[part 2 of 2: package /MICROSAR/Dcm_swc/ComponentTypes]
AUTOSAR XML (schema 00048)
package /MICROSAR/Dcm_swc/ComponentTypes
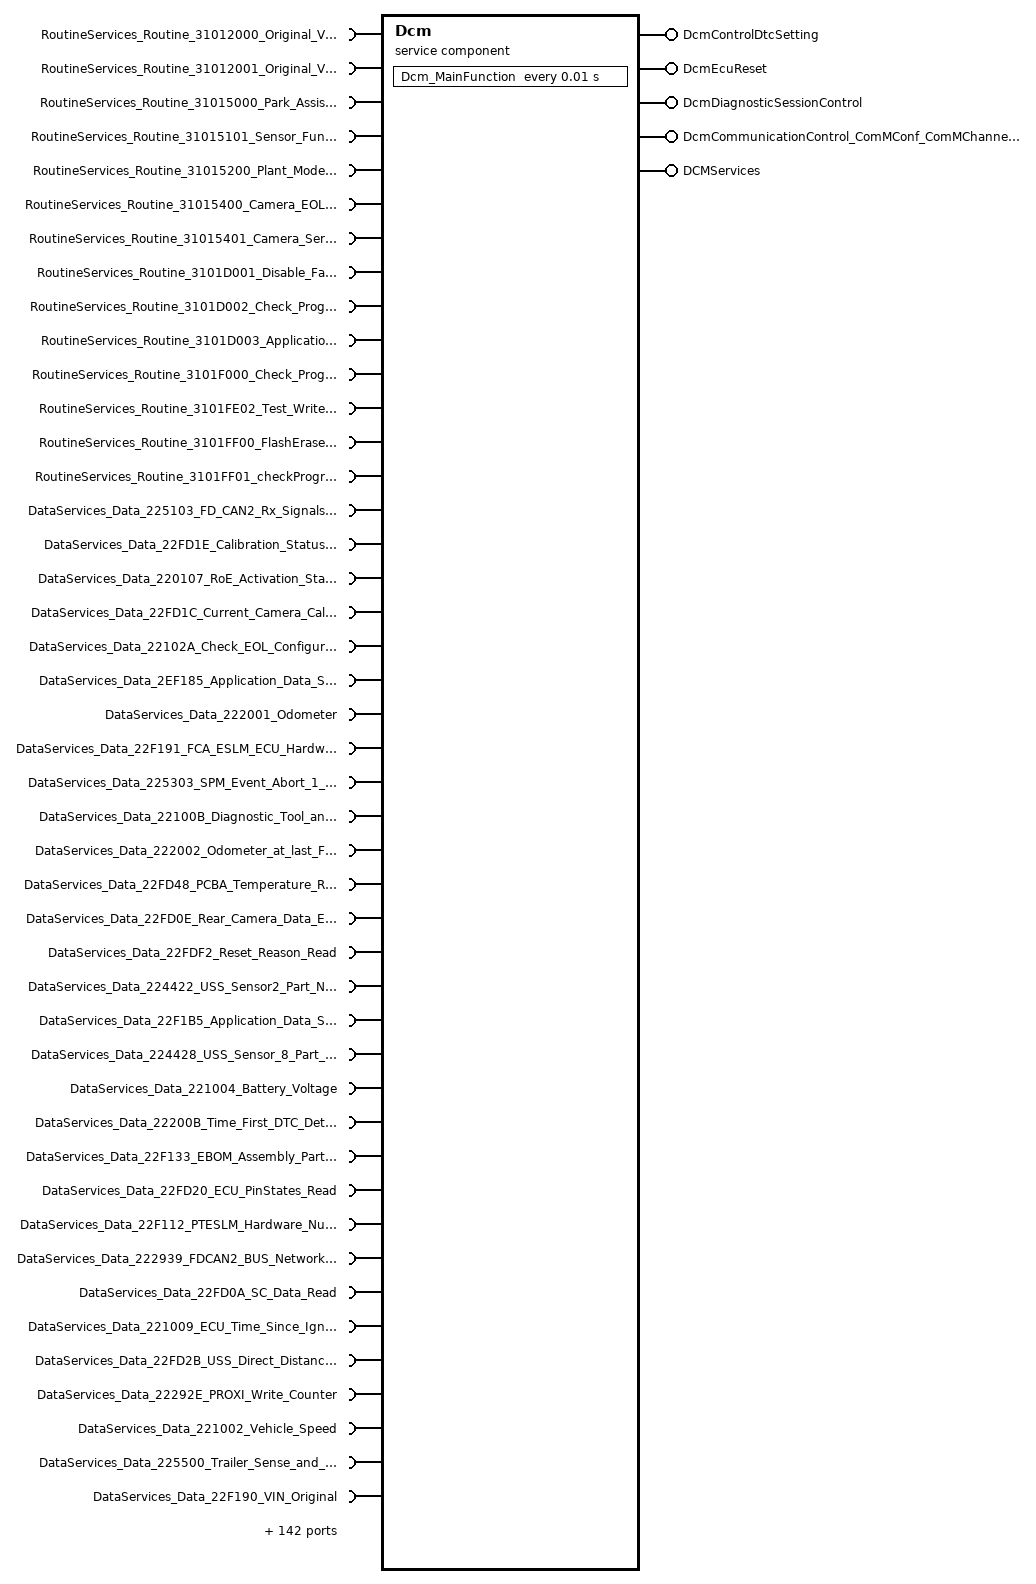
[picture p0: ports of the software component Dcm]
  service sw component type Dcm: category=SERVICE_COMPONENT
    5 x provide port:
      DcmControlDtcSetting: provided-interface=DcmControlDtcSetting
      DcmEcuReset: mode-switch-sender-com-spec{mode-group=DcmEcuReset, mode-switched-ack=timeout=0}, provided-interface=DcmEcuReset
      DcmDiagnosticSessionControl: provided-interface=DcmDiagnosticSessionControl
      DcmCommunicationControl_ComMConf_ComMChannel_CN_FDCAN2_28a8fc44: provided-interface=DcmCommunicationControl_ComMConf_ComMChannel_CN_FDCAN2_28a8fc44
      DCMServices: provided-interface=DCMServices
    186 x require port:
      RoutineServices_Routine_31012000_Original_VIN_Lock: required-interface=RoutineServices_Routine_31012000_Original_VIN_Lock
      RoutineServices_Routine_31012001_Original_VIN_Unlock: required-interface=RoutineServices_Routine_31012001_Original_VIN_Unlock
      RoutineServices_Routine_31015000_Park_Assist_ON_OFF_State_Start: required-interface=RoutineServices_Routine_31015000_Park_Assist_ON_OFF_State_Start
      RoutineServices_Routine_31015101_Sensor_Functional_Test_Start: required-interface=RoutineServices_Routine_31015101_Sensor_Functional_Test_Start
      RoutineServices_Routine_31015200_Plant_Mode_Routine_Start: required-interface=RoutineServices_Routine_31015200_Plant_Mode_Routine_Start
      RoutineServices_Routine_31015400_Camera_EOL_Calibration_Start: required-interface=RoutineServices_Routine_31015400_Camera_EOL_Calibration_Start
      RoutineServices_Routine_31015401_Camera_Service_Calibration_Start: required-interface=RoutineServices_Routine_31015401_Camera_Service_Calibration_Start
      RoutineServices_Routine_3101D001_Disable_Fail_safe_reaction_Start: required-interface=RoutineServices_Routine_3101D001_Disable_Fail_safe_reaction_Start
      RoutineServices_Routine_3101D002_Check_Programming_Preconditions_Start: required-interface=RoutineServices_Routine_3101D002_Check_Programming_Preconditions_Start
      RoutineServices_Routine_3101D003_Application_Logical_Block_Hash: required-interface=RoutineServices_Routine_3101D003_Application_Logical_Block_Hash
      RoutineServices_Routine_3101F000_Check_Program_Start: required-interface=RoutineServices_Routine_3101F000_Check_Program_Start
      RoutineServices_Routine_3101FE02_Test_Write_PMIC_Register_Start: required-interface=RoutineServices_Routine_3101FE02_Test_Write_PMIC_Register_Start
      RoutineServices_Routine_3101FF00_FlashErase_Start: required-interface=RoutineServices_Routine_3101FF00_FlashErase_Start
      RoutineServices_Routine_3101FF01_checkProgrammingDependencies_FlashChecksum_Start: required-interface=RoutineServices_Routine_3101FF01_checkProgrammingDependencies_FlashChecksum_Start
      DataServices_Data_225103_FD_CAN2_Rx_Signals_Read: required-interface=DataServices_Data_225103_FD_CAN2_Rx_Signals_Read
      DataServices_Data_22FD1E_Calibration_Status_Read: required-interface=DataServices_Data_22FD1E_Calibration_Status_Read
      DataServices_Data_220107_RoE_Activation_State: required-interface=DataServices_Data_220107_RoE_Activation_State
      DataServices_Data_22FD1C_Current_Camera_Calibration_Data_Read: required-interface=DataServices_Data_22FD1C_Current_Camera_Calibration_Data_Read
      DataServices_Data_22102A_Check_EOL_Configuration_Data: required-interface=DataServices_Data_22102A_Check_EOL_Configuration_Data
      DataServices_Data_2EF185_Application_Data_Software_Fingerprint_Writing_Information: required-interface=DataServices_Data_2EF185_Application_Data_Software_Fingerprint_Writing_Information
      DataServices_Data_222001_Odometer: required-interface=DataServices_Data_222001_Odometer
      DataServices_Data_22F191_FCA_ESLM_ECU_Hardware_Number: required-interface=DataServices_Data_22F191_FCA_ESLM_ECU_Hardware_Number
      DataServices_Data_225303_SPM_Event_Abort_1_Read: required-interface=DataServices_Data_225303_SPM_Event_Abort_1_Read
      DataServices_Data_22100B_Diagnostic_Tool_and_Session_Status: required-interface=DataServices_Data_22100B_Diagnostic_Tool_and_Session_Status
      DataServices_Data_222002_Odometer_at_last_Flash_programming: required-interface=DataServices_Data_222002_Odometer_at_last_Flash_programming
      DataServices_Data_22FD48_PCBA_Temperature_Read: required-interface=DataServices_Data_22FD48_PCBA_Temperature_Read
      DataServices_Data_22FD0E_Rear_Camera_Data_EEPROM_Read: required-interface=DataServices_Data_22FD0E_Rear_Camera_Data_EEPROM_Read
      DataServices_Data_22FDF2_Reset_Reason_Read: required-interface=DataServices_Data_22FDF2_Reset_Reason_Read
      DataServices_Data_224422_USS_Sensor2_Part_Number_Read: required-interface=DataServices_Data_224422_USS_Sensor2_Part_Number_Read
      DataServices_Data_22F1B5_Application_Data_Software_Fingerprint_Reading_Information: required-interface=DataServices_Data_22F1B5_Application_Data_Software_Fingerprint_Reading_Information
      DataServices_Data_224428_USS_Sensor_8_Part_Number_Read: required-interface=DataServices_Data_224428_USS_Sensor_8_Part_Number_Read
      DataServices_Data_221004_Battery_Voltage: required-interface=DataServices_Data_221004_Battery_Voltage
      DataServices_Data_22200B_Time_First_DTC_Detection: required-interface=DataServices_Data_22200B_Time_First_DTC_Detection
      DataServices_Data_22F133_EBOM_Assembly_Part_Number: required-interface=DataServices_Data_22F133_EBOM_Assembly_Part_Number
      DataServices_Data_22FD20_ECU_PinStates_Read: required-interface=DataServices_Data_22FD20_ECU_PinStates_Read
      DataServices_Data_22F112_PTESLM_Hardware_Number: required-interface=DataServices_Data_22F112_PTESLM_Hardware_Number
      DataServices_Data_222939_FDCAN2_BUS_Network_WakeUp_Reason: required-interface=DataServices_Data_222939_FDCAN2_BUS_Network_WakeUp_Reason
      DataServices_Data_22FD0A_SC_Data_Read: required-interface=DataServices_Data_22FD0A_SC_Data_Read
      DataServices_Data_221009_ECU_Time_Since_Ignition_ON: required-interface=DataServices_Data_221009_ECU_Time_Since_Ignition_ON
      DataServices_Data_22FD2B_USS_Direct_Distance_0xFD2B_Read: required-interface=DataServices_Data_22FD2B_USS_Direct_Distance_0xFD2B_Read
      DataServices_Data_22292E_PROXI_Write_Counter: required-interface=DataServices_Data_22292E_PROXI_Write_Counter
      DataServices_Data_221002_Vehicle_Speed: required-interface=DataServices_Data_221002_Vehicle_Speed
      DataServices_Data_225500_Trailer_Sense_and_Drive_Function_Data_Read: required-interface=DataServices_Data_225500_Trailer_Sense_and_Drive_Function_Data_Read
      DataServices_Data_22F190_VIN_Original: required-interface=DataServices_Data_22F190_VIN_Original
      DataServices_Data_22FD42_Failsafe_Behaviour_Read: required-interface=DataServices_Data_22FD42_Failsafe_Behaviour_Read
      DataServices_Data_225302_Rear_Braking_Event_3_Read: required-interface=DataServices_Data_225302_Rear_Braking_Event_3_Read
      DataServices_Data_225300_Rear_Braking_Event_1_Read: required-interface=DataServices_Data_225300_Rear_Braking_Event_1_Read
      DataServices_Data_22FD2C_USS_Temperature_Read: required-interface=DataServices_Data_22FD2C_USS_Temperature_Read
      DataServices_Data_222003_Boot_Software_Programming_Attempt_Counter: required-interface=DataServices_Data_222003_Boot_Software_Programming_Attempt_Counter
      DataServices_Data_225501_Trailer_coupler_sense_detection_Function_Data_Read: required-interface=DataServices_Data_225501_Trailer_coupler_sense_detection_Function_Data_Read
      DataServices_Data_22F132_EBOM_ECU_Part_Number: required-interface=DataServices_Data_22F132_EBOM_ECU_Part_Number
      DataServices_Data_22F1B3_Boot_Software_Fingerprint_Reading_Information: required-interface=DataServices_Data_22F1B3_Boot_Software_Fingerprint_Reading_Information
      DataServices_Data_2F5001_Gear_Position_Read: required-interface=DataServices_Data_2F5001_Gear_Position_Read
      DataServices_Data_22F1B4_Application_Software_Fingerprint_Reading_Information: required-interface=DataServices_Data_22F1B4_Application_Software_Fingerprint_Reading_Information
      DataServices_Data_22FD28_USS_Ringing_Frequency_Read: required-interface=DataServices_Data_22FD28_USS_Ringing_Frequency_Read
      DataServices_Data_22200D_Odometer_Last_Clear_Data_Trouble_Code_DTC: required-interface=DataServices_Data_22200D_Odometer_Last_Clear_Data_Trouble_Code_DTC
      DataServices_Data_22FD2D_USS_Sensor_ID_IME_SN_Read: required-interface=DataServices_Data_22FD2D_USS_Sensor_ID_IME_SN_Read
      DataServices_Data_22F134_CODEP_assembly_part_number: required-interface=DataServices_Data_22F134_CODEP_assembly_part_number
      DataServices_Data_225301_Rear_Braking_Event_2_Read: required-interface=DataServices_Data_225301_Rear_Braking_Event_2_Read
      DataServices_Data_22201A_Application_Software_Programming_Attempt_Counter: required-interface=DataServices_Data_22201A_Application_Software_Programming_Attempt_Counter
      DataServices_Data_225102_FD_CAN14_Rx_Signals_Read: required-interface=DataServices_Data_225102_FD_CAN14_Rx_Signals_Read
      DataServices_Data_22F1B0_VIN_Current: required-interface=DataServices_Data_22F1B0_VIN_Current
      DataServices_Data_22FD15_Magna_Production_HW_Number_Read: required-interface=DataServices_Data_22FD15_Magna_Production_HW_Number_Read
      DataServices_Data_22201B_Application_Data_Software_Programming_Attempt_Counter: required-interface=DataServices_Data_22201B_Application_Data_Software_Programming_Attempt_Counter
      DataServices_Data_22200C_Time_Since_Ignition_ON_of_first_DTC_Detection: required-interface=DataServices_Data_22200C_Time_Since_Ignition_ON_of_first_DTC_Detection
      DataServices_Data_22FD31_Magna_EOL_Coding_State_Read: required-interface=DataServices_Data_22FD31_Magna_EOL_Coding_State_Read
      DataServices_Data_224451_EOL_Calibration_State_Read: required-interface=DataServices_Data_224451_EOL_Calibration_State_Read
      DataServices_Data_22F155_Software_Supplier_Identification: required-interface=DataServices_Data_22F155_Software_Supplier_Identification
      DataServices_Data_22F110_ECU_Diagnostic_Identification: required-interface=DataServices_Data_22F110_ECU_Diagnostic_Identification
      DataServices_Data_222024_Read_ECU_PROXI_Data: required-interface=DataServices_Data_222024_Read_ECU_PROXI_Data
      DataServices_Data_22FD47_SoC_Temperature_0xFD47_Read: required-interface=DataServices_Data_22FD47_SoC_Temperature_0xFD47_Read
      DataServices_Data_222013_VIN_Lock_State_Read: required-interface=DataServices_Data_222013_VIN_Lock_State_Read
      DataServices_Data_22F154_Hardware_Supplier_Identification: required-interface=DataServices_Data_22F154_Hardware_Supplier_Identification
      DataServices_Data_22442A_USS_Sensor_10_Part_Number_Read: required-interface=DataServices_Data_22442A_USS_Sensor_10_Part_Number_Read
      DataServices_Data_22FD17_Magna_Production_HW_Version_information_Read: required-interface=DataServices_Data_22FD17_Magna_Production_HW_Version_information_Read
      DataServices_Data_225104_FD_CAN14_Tx_Signals_Read: required-interface=DataServices_Data_225104_FD_CAN14_Tx_Signals_Read
      DataServices_Data_22FD07_OC_Result_Read: required-interface=DataServices_Data_22FD07_OC_Result_Read
      DataServices_Data_22F18C_ECU_Serial_Number: required-interface=DataServices_Data_22F18C_ECU_Serial_Number
      DataServices_Data_224421_USS_Sensor_1_Part_Number_Read: required-interface=DataServices_Data_224421_USS_Sensor_1_Part_Number_Read
      DataServices_Data_22FD46_Camera_Power_Supply_Read: required-interface=DataServices_Data_22FD46_Camera_Power_Supply_Read
      DataServices_Data_22201F_Boot_Failure_Reason_Read: required-interface=DataServices_Data_22201F_Boot_Failure_Reason_Read
      DataServices_Data_22F18B_FCA_ESLM_ECU_Software_Application_Number: required-interface=DataServices_Data_22F18B_FCA_ESLM_ECU_Software_Application_Number
      DataServices_Data_22200A_Ignition_ON_Counter: required-interface=DataServices_Data_22200A_Ignition_ON_Counter
      DataServices_Data_22F10D_Diagnostic_Specification_Information: required-interface=DataServices_Data_22F10D_Diagnostic_Specification_Information
      DataServices_Data_22F192_Supplier_ECU_Hardware_Part_Number: required-interface=DataServices_Data_22F192_Supplier_ECU_Hardware_Part_Number
      DataServices_Data_222026_CAN_Overrun_Counters: required-interface=DataServices_Data_222026_CAN_Overrun_Counters
      DataServices_Data_22F193_Supplier_ECU_Hardware_Version_Number: required-interface=DataServices_Data_22F193_Supplier_ECU_Hardware_Version_Number
      DataServices_Data_22F1A2_Vector_Delivery_ID: required-interface=DataServices_Data_22F1A2_Vector_Delivery_ID
      DataServices_Data_22FD0D_Left_Camera_Data_EEPROM_Read: required-interface=DataServices_Data_22FD0D_Left_Camera_Data_EEPROM_Read
      DataServices_Data_225100_SPM_status_Read: required-interface=DataServices_Data_225100_SPM_status_Read
      DataServices_Data_22FD0C_Front_Camera_Data_EEPROM_Read: required-interface=DataServices_Data_22FD0C_Front_Camera_Data_EEPROM_Read
      DataServices_Data_220103_VIN_Lock_Status: required-interface=DataServices_Data_220103_VIN_Lock_Status
      DataServices_Data_22FDF0_ECU_shutdown_process_Read: required-interface=DataServices_Data_22FDF0_ECU_shutdown_process_Read
      DataServices_Data_22191D_Time_of_Power_Latch: required-interface=DataServices_Data_22191D_Time_of_Power_Latch
      DataServices_Data_22FDF1_CPU_Load_Read: required-interface=DataServices_Data_22FDF1_CPU_Load_Read
      DataServices_Data_22F182_Application_Data_Identification: required-interface=DataServices_Data_22F182_Application_Data_Identification
      DataServices_Data_22442B_USS_Sensor_11_Part_Number_Read: required-interface=DataServices_Data_22442B_USS_Sensor_11_Part_Number_Read
      DataServices_Data_2EF184_Application_Software_Fingerprint_writing_information: required-interface=DataServices_Data_2EF184_Application_Software_Fingerprint_writing_information
      DataServices_Data_22F180_Boot_Software_Version_Information: required-interface=DataServices_Data_22F180_Boot_Software_Version_Information
      DataServices_Data_22FD29_USS_Driving_Frequency_Read: required-interface=DataServices_Data_22FD29_USS_Driving_Frequency_Read
      DataServices_Data_22FD2A_USS_Ringing_Time_Read: required-interface=DataServices_Data_22FD2A_USS_Ringing_Time_Read
      DataServices_Data_221921_Operational_Mode_Status: required-interface=DataServices_Data_221921_Operational_Mode_Status
      DataServices_Data_225304_SPM_Event_Abort_2_Read: required-interface=DataServices_Data_225304_SPM_Event_Abort_2_Read
      DataServices_Data_22F1A1_Configuration_Code: required-interface=DataServices_Data_22F1A1_Configuration_Code
      DataServices_Data_22F195_Supplier_ECU_Software_Version_Number: required-interface=DataServices_Data_22F195_Supplier_ECU_Software_Version_Number
      DataServices_Data_22FD16_Magna_Production_ICT_Data_Read: required-interface=DataServices_Data_22FD16_Magna_Production_ICT_Data_Read
      DataServices_Data_224429_USS_Sensor_9_Part_Number_Read: required-interface=DataServices_Data_224429_USS_Sensor_9_Part_Number_Read
      DataServices_Data_222010_Programming_Status: required-interface=DataServices_Data_222010_Programming_Status
      DataServices_Data_22F187_CODEP_ECU_Part_Number: required-interface=DataServices_Data_22F187_CODEP_ECU_Part_Number
      DataServices_Data_2E2023_PROXI_Data: required-interface=DataServices_Data_2E2023_PROXI_Data
      DataServices_Data_22FD49_SoC_Die_Temperature_ID_0xFD49_Read: required-interface=DataServices_Data_22FD49_SoC_Die_Temperature_ID_0xFD49_Read
      DataServices_Data_22FD08_OC_Data_Read: required-interface=DataServices_Data_22FD08_OC_Data_Read
      DataServices_Data_22FD61_Vehicle_Variant_Coding_Data_Read: required-interface=DataServices_Data_22FD61_Vehicle_Variant_Coding_Data_Read
      DataServices_Data_22FD33_Magna_Testing_2_Read: required-interface=DataServices_Data_22FD33_Magna_Testing_2_Read
      DataServices_Data_22F181_Application_Software_Identification: required-interface=DataServices_Data_22F181_Application_Software_Identification
      DataServices_Data_224427_USS_Sensor_7_Part_Number_Read: required-interface=DataServices_Data_224427_USS_Sensor_7_Part_Number_Read
      DataServices_Data_22F188_FCA_ESLM_ECU_Software_Number: required-interface=DataServices_Data_22F188_FCA_ESLM_ECU_Software_Number
      DataServices_Data_22442C_USS_Sensor_12_Part_Number_Read: required-interface=DataServices_Data_22442C_USS_Sensor_12_Part_Number_Read
      DataServices_Data_224426_USS_Sensor_6_Part_Number_Read: required-interface=DataServices_Data_224426_USS_Sensor_6_Part_Number_Read
      DataServices_Data_22F10B_ECU_Qualification: required-interface=DataServices_Data_22F10B_ECU_Qualification
      DataServices_Data_225201_Plant_Mode_Status_Read: required-interface=DataServices_Data_225201_Plant_Mode_Status_Read
      DataServices_Data_222008_ECU_Life_Time_Not_Volatile_Memory: required-interface=DataServices_Data_222008_ECU_Life_Time_Not_Volatile_Memory
      DataServices_Data_22F18A_FCA_ESLM_ECU_Software_Calibration_Number: required-interface=DataServices_Data_22F18A_FCA_ESLM_ECU_Software_Calibration_Number
      DataServices_Data_224425_USS_Sensor_5_Part_Number_Read: required-interface=DataServices_Data_224425_USS_Sensor_5_Part_Number_Read
      DataServices_Data_22F122_Software_EBOM_Part_Number: required-interface=DataServices_Data_22F122_Software_EBOM_Part_Number
      DataServices_Data_225105_FD_CAN2_Tx_Signals_Read: required-interface=DataServices_Data_225105_FD_CAN2_Tx_Signals_Read
      DataServices_Data_22F1A0_System_Identification_Data: required-interface=DataServices_Data_22F1A0_System_Identification_Data
      DataServices_Data_22FD0F_Right_Camera_Data_EEPROM_Read: required-interface=DataServices_Data_22FD0F_Right_Camera_Data_EEPROM_Read
      DataServices_Data_224424_USS_Sensor_4_Part_Number_Read: required-interface=DataServices_Data_224424_USS_Sensor_4_Part_Number_Read
      DataServices_Data_221008_ECU_Life_Time: required-interface=DataServices_Data_221008_ECU_Life_Time
      DataServices_Data_22F194_Supplier_ECU_Software_Part_Number: required-interface=DataServices_Data_22F194_Supplier_ECU_Software_Part_Number
      DataServices_Data_224423_USS_Sensor_3_Part_Number_Read: required-interface=DataServices_Data_224423_USS_Sensor_3_Part_Number_Read
      DataServices_Data_22FD2E_USS_Sensor_ID_Murata_SN_Read: required-interface=DataServices_Data_22FD2E_USS_Sensor_ID_Murata_SN_Read
      DataServices_Data_22F1A6_Message_Matrix: required-interface=DataServices_Data_22F1A6_Message_Matrix
      DataServices_Data_222945_Flow_Control_Test: required-interface=DataServices_Data_222945_Flow_Control_Test
      DataServices_Data_22F186_Active_Diagnostic_Session: required-interface=DataServices_Data_22F186_Active_Diagnostic_Session
      Dcm_Read_Mode: mode-switch-receiver-com-spec=enhanced-mode-api=true, required-interface=Dcm_Read_Mode
      RoutineServices_Routine_3101FE01_Calibration_Data_Reset_Start: required-interface=RoutineServices_Routine_3101FE01_Calibration_Data_Reset_Start
      RoutineServices_Routine_3101FE0E_Test_Pattern_Control_Start: required-interface=RoutineServices_Routine_3101FE0E_Test_Pattern_Control_Start
      RoutineServices_Routine_3101FF03_Test_Read_PMIC_Register_Start: required-interface=RoutineServices_Routine_3101FF03_Test_Read_PMIC_Register_Start
      DataServices_Data_22FD01_Previous_Camera_Calibration_Data: required-interface=DataServices_Data_22FD01_Previous_Camera_Calibration_Data
      DataServices_Data_22FD60_ECU_Software_Status_Read: required-interface=DataServices_Data_22FD60_ECU_Software_Status_Read
      DataServices_Data_22FD14_FD14_Magna_Production_Date_Read: required-interface=DataServices_Data_22FD14_FD14_Magna_Production_Date_Read
      DataServices_Data_22FD38_Programmed_Assembly: required-interface=DataServices_Data_22FD38_Programmed_Assembly
      DataServices_Data_22FD00_Plant_Camera_Calibration_Data: required-interface=DataServices_Data_22FD00_Plant_Camera_Calibration_Data
      DataServices_Data_225305_SPM_Event_Abort_3_Read: required-interface=DataServices_Data_225305_SPM_Event_Abort_3_Read
      DataServices_Data_22FD1D_PCB_Serial_Number: required-interface=DataServices_Data_22FD1D_PCB_Serial_Number
      DataServices_Data_22FD13_Magna_Software_Version: required-interface=DataServices_Data_22FD13_Magna_Software_Version
      RoutineServices_Routine_31011000_USS_Debug_Signals_Enable_Disable_Start: required-interface=RoutineServices_Routine_31011000_USS_Debug_Signals_Enable_Disable_Start
      RoutineServices_Routine_31013000_XCP_Enable_Disable_Start: required-interface=RoutineServices_Routine_31013000_XCP_Enable_Disable_Start
      DataServices_Data_22F111_Public_Certificates_Regional_Support_Read: required-interface=DataServices_Data_22F111_Public_Certificates_Regional_Support_Read
      DataServices_Data_222032_Secure_Log_Read: required-interface=DataServices_Data_222032_Secure_Log_Read
      DataServices_Data_222959_Hosted_App_Firmware_Cal_Config_Data_Header_Info_Read: required-interface=DataServices_Data_222959_Hosted_App_Firmware_Cal_Config_Data_Header_Info_Read
      DataServices_Data_22100C_Security_Status_Read: required-interface=DataServices_Data_22100C_Security_Status_Read
      DataServices_Data_222954_Policy_Type_Read: required-interface=DataServices_Data_222954_Policy_Type_Read
      DataServices_Data_222030_Authenticated_Diagnostic_Previous_Access_Read: required-interface=DataServices_Data_222030_Authenticated_Diagnostic_Previous_Access_Read
      DataServices_Data_2EFD4E_Reset_NVM_Write: required-interface=DataServices_Data_2EFD4E_Reset_NVM_Write
      DataServices_Data_22FD64_ASIL_B_Fault_Status_Read: required-interface=DataServices_Data_22FD64_ASIL_B_Fault_Status_Read
      DataServices_Data_220108_Authenticated_Diagnostics_Active_Role_Read: required-interface=DataServices_Data_220108_Authenticated_Diagnostics_Active_Role_Read
      DataServices_Data_22295F_DCL_and_Cerstore_Header_Info_Read: required-interface=DataServices_Data_22295F_DCL_and_Cerstore_Header_Info_Read
      DataServices_Data_222031_Disallowed_Certificate_List_Read: required-interface=DataServices_Data_222031_Disallowed_Certificate_List_Read
      DataServices_Data_22295A_Hosted_App_Firmware_Cal_Config_Data_Header_UUID_Read: required-interface=DataServices_Data_22295A_Hosted_App_Firmware_Cal_Config_Data_Header_UUID_Read
      DataServices_Data_222958_Hosted_App_firmware_Header_UUID_Read: required-interface=DataServices_Data_222958_Hosted_App_firmware_Header_UUID_Read
      DataServices_Data_222957_Hosted_App_Firmware_Header_Info_Read: required-interface=DataServices_Data_222957_Hosted_App_Firmware_Header_Info_Read
      DataServices_Data_22FD62_ASIL_QM_Fault_Status_Read: required-interface=DataServices_Data_22FD62_ASIL_QM_Fault_Status_Read
      DataServices_Data_22FD86_Functional_Settings_Read: required-interface=DataServices_Data_22FD86_Functional_Settings_Read
      DataServices_Data_225109_Rear_Sensor_HealthBlockage_LiveDetection_Check_Read: required-interface=DataServices_Data_225109_Rear_Sensor_HealthBlockage_LiveDetection_Check_Read
      DataServices_Data_225107_Front_Sensor_HealthBlockage_LiveDetection_Check_Read: required-interface=DataServices_Data_225107_Front_Sensor_HealthBlockage_LiveDetection_Check_Read
      DataServices_Data_22FD4A_Ultrasonic_Sensors_Power_supply_and_Current_Level_Read: required-interface=DataServices_Data_22FD4A_Ultrasonic_Sensors_Power_supply_and_Current_Level_Read
      DataServices_Data_22FD65_FuSa_Module_Status_Read: required-interface=DataServices_Data_22FD65_FuSa_Module_Status_Read
      DataServices_Data_222951_Certificate_Store_UUID_Read: required-interface=DataServices_Data_222951_Certificate_Store_UUID_Read
      DataServices_Data_22FD66_Camera_occlusion_and_low_light_status_Read: required-interface=DataServices_Data_22FD66_Camera_occlusion_and_low_light_status_Read
      DataServices_Data_22FD67_Camera_DLD_Status_Read: required-interface=DataServices_Data_22FD67_Camera_DLD_Status_Read
      DataServices_Data_22295B_HTA_Header_Info_Read: required-interface=DataServices_Data_22295B_HTA_Header_Info_Read
      DataServices_Data_22FD43_Active_Safe_State_Read: required-interface=DataServices_Data_22FD43_Active_Safe_State_Read
      DataServices_Data_22FD44_Error_Flags_Read: required-interface=DataServices_Data_22FD44_Error_Flags_Read
      DataServices_Data_22295E_DCL_Header_UUID_Read: required-interface=DataServices_Data_22295E_DCL_Header_UUID_Read
      DataServices_Data_22295C_HTA_Header_UUID_Read: required-interface=DataServices_Data_22295C_HTA_Header_UUID_Read
      DataServices_Data_22FD74_PHY_Tunning_Error_And_Buffer_Mark_Error_Read: required-interface=DataServices_Data_22FD74_PHY_Tunning_Error_And_Buffer_Mark_Error_Read
      RoutineServices_Routine_31015502_TRSC_Trailer_Calibration_Memory_Clear_Start: required-interface=RoutineServices_Routine_31015502_TRSC_Trailer_Calibration_Memory_Clear_Start
      DataServices_Data_22FDF7_Intrinsic_Camera_NvM_Data_Read: required-interface=DataServices_Data_22FDF7_Intrinsic_Camera_NvM_Data_Read
      DataServices_Data_22FDF6_RunTimeStatsData_Read: required-interface=DataServices_Data_22FDF6_RunTimeStatsData_Read
      DataServices_Data_22FD04_USS_Sensor_tuning_values_Read: required-interface=DataServices_Data_22FD04_USS_Sensor_tuning_values_Read
      Dcm_Read_ModeProgPreconditionCheck: mode-switch-receiver-com-spec=enhanced-mode-api=true, required-interface=Dcm_Read_ModeProgPreconditionCheck
      DataServices_Data_22FDF8_StackUsage_Read: required-interface=DataServices_Data_22FDF8_StackUsage_Read
      DataServices_Data_22FDF5_PerformanceStatEnable_Read: required-interface=DataServices_Data_22FDF5_PerformanceStatEnable_Read
    behavior DcmInternalBehavior: data-type-mapping=DcmMappingSet, handle-termination-and-restart=NO-SUPPORT, included-data-type-set=data-type=[Dcm_ConfirmationStatusType, Dcm_OpStatusType, Dcm_NegativeResponseCodeType, Dcm_ProtocolType, Dcm_RequestKindType, Dcm_SecLevelType, Dcm_SesCtrlType, Dcm_ControlDtcSettingType, Dcm_EcuResetType, Dcm_DiagnosticSessionControlType, Dcm_CommunicationModeType]
      timing event Timer_Dcm_MainFunction: start-on-event=Dcm_MainFunction, period=0.01
      6 x operation invoked event:
        OpEventGetActiveProtocol_GetActiveProtocol_DCMServices: start-on-event=GetActiveProtocol, operation=DCMServices.GetActiveProtocol
        OpEventGetSesCtrlType_GetSesCtrlType_DCMServices: start-on-event=GetSesCtrlType, operation=DCMServices.GetSesCtrlType
        OpEventResetToDefaultSession_ResetToDefaultSession_DCMServices: start-on-event=ResetToDefaultSession, operation=DCMServices.ResetToDefaultSession
        OpEventGetSecurityLevel_GetSecurityLevel_DCMServices: start-on-event=GetSecurityLevel, operation=DCMServices.GetSecurityLevel
        OpEventSetActiveDiagnostic_SetActiveDiagnostic_DCMServices: start-on-event=SetActiveDiagnostic, operation=DCMServices.SetActiveDiagnostic
        OpEventGetRequestKind_GetRequestKind_DCMServices: start-on-event=GetRequestKind, operation=DCMServices.GetRequestKind
      port-api-options:
        enable-take-address=true, indirect-api=false, port=DcmControlDtcSetting
        enable-take-address=true, indirect-api=false, port=DcmEcuReset
        enable-take-address=true, indirect-api=false, port=DcmDiagnosticSessionControl
        enable-take-address=true, indirect-api=false, port=DcmCommunicationControl_ComMConf_ComMChannel_CN_FDCAN2_28a8fc44
        enable-take-address=true, indirect-api=false, port=DCMServices
        enable-take-address=true, indirect-api=false, port=RoutineServices_Routine_31012000_Original_VIN_Lock
        enable-take-address=true, indirect-api=false, port=RoutineServices_Routine_31012001_Original_VIN_Unlock
        enable-take-address=true, indirect-api=false, port=RoutineServices_Routine_31015000_Park_Assist_ON_OFF_State_Start
        enable-take-address=true, indirect-api=false, port=RoutineServices_Routine_31015101_Sensor_Functional_Test_Start
        enable-take-address=true, indirect-api=false, port=RoutineServices_Routine_31015200_Plant_Mode_Routine_Start
        enable-take-address=true, indirect-api=false, port=RoutineServices_Routine_31015400_Camera_EOL_Calibration_Start
        enable-take-address=true, indirect-api=false, port=RoutineServices_Routine_31015401_Camera_Service_Calibration_Start
        enable-take-address=true, indirect-api=false, port=RoutineServices_Routine_3101D001_Disable_Fail_safe_reaction_Start
        enable-take-address=true, indirect-api=false, port=RoutineServices_Routine_3101D002_Check_Programming_Preconditions_Start
        enable-take-address=true, indirect-api=false, port=RoutineServices_Routine_3101D003_Application_Logical_Block_Hash
        enable-take-address=true, indirect-api=false, port=RoutineServices_Routine_3101F000_Check_Program_Start
        enable-take-address=true, indirect-api=false, port=RoutineServices_Routine_3101FE02_Test_Write_PMIC_Register_Start
        enable-take-address=true, indirect-api=false, port=RoutineServices_Routine_3101FF00_FlashErase_Start
        enable-take-address=true, indirect-api=false, port=RoutineServices_Routine_3101FF01_checkProgrammingDependencies_FlashChecksum_Start
        enable-take-address=true, indirect-api=false, port=DataServices_Data_225103_FD_CAN2_Rx_Signals_Read
        enable-take-address=true, indirect-api=false, port=DataServices_Data_22FD1E_Calibration_Status_Read
        enable-take-address=true, indirect-api=false, port=DataServices_Data_220107_RoE_Activation_State
        enable-take-address=true, indirect-api=false, port=DataServices_Data_22FD1C_Current_Camera_Calibration_Data_Read
        enable-take-address=true, indirect-api=false, port=DataServices_Data_22102A_Check_EOL_Configuration_Data
        enable-take-address=true, indirect-api=false, port=DataServices_Data_2EF185_Application_Data_Software_Fingerprint_Writing_Information
        enable-take-address=true, indirect-api=false, port=DataServices_Data_222001_Odometer
        enable-take-address=true, indirect-api=false, port=DataServices_Data_22F191_FCA_ESLM_ECU_Hardware_Number
        enable-take-address=true, indirect-api=false, port=DataServices_Data_225303_SPM_Event_Abort_1_Read
        enable-take-address=true, indirect-api=false, port=DataServices_Data_22100B_Diagnostic_Tool_and_Session_Status
        enable-take-address=true, indirect-api=false, port=DataServices_Data_222002_Odometer_at_last_Flash_programming
        enable-take-address=true, indirect-api=false, port=DataServices_Data_22FD48_PCBA_Temperature_Read
        enable-take-address=true, indirect-api=false, port=DataServices_Data_22FD0E_Rear_Camera_Data_EEPROM_Read
        enable-take-address=true, indirect-api=false, port=DataServices_Data_22FDF2_Reset_Reason_Read
        enable-take-address=true, indirect-api=false, port=DataServices_Data_224422_USS_Sensor2_Part_Number_Read
        enable-take-address=true, indirect-api=false, port=DataServices_Data_22F1B5_Application_Data_Software_Fingerprint_Reading_Information
        enable-take-address=true, indirect-api=false, port=DataServices_Data_224428_USS_Sensor_8_Part_Number_Read
        enable-take-address=true, indirect-api=false, port=DataServices_Data_221004_Battery_Voltage
        enable-take-address=true, indirect-api=false, port=DataServices_Data_22200B_Time_First_DTC_Detection
        enable-take-address=true, indirect-api=false, port=DataServices_Data_22F133_EBOM_Assembly_Part_Number
        enable-take-address=true, indirect-api=false, port=DataServices_Data_22FD20_ECU_PinStates_Read
        enable-take-address=true, indirect-api=false, port=DataServices_Data_22F112_PTESLM_Hardware_Number
        enable-take-address=true, indirect-api=false, port=DataServices_Data_222939_FDCAN2_BUS_Network_WakeUp_Reason
        enable-take-address=true, indirect-api=false, port=DataServices_Data_22FD0A_SC_Data_Read
        enable-take-address=true, indirect-api=false, port=DataServices_Data_221009_ECU_Time_Since_Ignition_ON
        enable-take-address=true, indirect-api=false, port=DataServices_Data_22FD2B_USS_Direct_Distance_0xFD2B_Read
        enable-take-address=true, indirect-api=false, port=DataServices_Data_22292E_PROXI_Write_Counter
        enable-take-address=true, indirect-api=false, port=DataServices_Data_221002_Vehicle_Speed
        enable-take-address=true, indirect-api=false, port=DataServices_Data_225500_Trailer_Sense_and_Drive_Function_Data_Read
        enable-take-address=true, indirect-api=false, port=DataServices_Data_22F190_VIN_Original
        enable-take-address=true, indirect-api=false, port=DataServices_Data_22FD42_Failsafe_Behaviour_Read
        enable-take-address=true, indirect-api=false, port=DataServices_Data_225302_Rear_Braking_Event_3_Read
        enable-take-address=true, indirect-api=false, port=DataServices_Data_225300_Rear_Braking_Event_1_Read
        enable-take-address=true, indirect-api=false, port=DataServices_Data_22FD2C_USS_Temperature_Read
        enable-take-address=true, indirect-api=false, port=DataServices_Data_222003_Boot_Software_Programming_Attempt_Counter
        enable-take-address=true, indirect-api=false, port=DataServices_Data_225501_Trailer_coupler_sense_detection_Function_Data_Read
        enable-take-address=true, indirect-api=false, port=DataServices_Data_22F132_EBOM_ECU_Part_Number
        enable-take-address=true, indirect-api=false, port=DataServices_Data_22F1B3_Boot_Software_Fingerprint_Reading_Information
        enable-take-address=true, indirect-api=false, port=DataServices_Data_2F5001_Gear_Position_Read
        enable-take-address=true, indirect-api=false, port=DataServices_Data_22F1B4_Application_Software_Fingerprint_Reading_Information
        enable-take-address=true, indirect-api=false, port=DataServices_Data_22FD28_USS_Ringing_Frequency_Read
        enable-take-address=true, indirect-api=false, port=DataServices_Data_22200D_Odometer_Last_Clear_Data_Trouble_Code_DTC
        enable-take-address=true, indirect-api=false, port=DataServices_Data_22FD2D_USS_Sensor_ID_IME_SN_Read
        enable-take-address=true, indirect-api=false, port=DataServices_Data_22F134_CODEP_assembly_part_number
        enable-take-address=true, indirect-api=false, port=DataServices_Data_225301_Rear_Braking_Event_2_Read
        enable-take-address=true, indirect-api=false, port=DataServices_Data_22201A_Application_Software_Programming_Attempt_Counter
        enable-take-address=true, indirect-api=false, port=DataServices_Data_225102_FD_CAN14_Rx_Signals_Read
        enable-take-address=true, indirect-api=false, port=DataServices_Data_22F1B0_VIN_Current
        enable-take-address=true, indirect-api=false, port=DataServices_Data_22FD15_Magna_Production_HW_Number_Read
        enable-take-address=true, indirect-api=false, port=DataServices_Data_22201B_Application_Data_Software_Programming_Attempt_Counter
        enable-take-address=true, indirect-api=false, port=DataServices_Data_22200C_Time_Since_Ignition_ON_of_first_DTC_Detection
        enable-take-address=true, indirect-api=false, port=DataServices_Data_22FD31_Magna_EOL_Coding_State_Read
        enable-take-address=true, indirect-api=false, port=DataServices_Data_224451_EOL_Calibration_State_Read
        enable-take-address=true, indirect-api=false, port=DataServices_Data_22F155_Software_Supplier_Identification
        enable-take-address=true, indirect-api=false, port=DataServices_Data_22F110_ECU_Diagnostic_Identification
        enable-take-address=true, indirect-api=false, port=DataServices_Data_222024_Read_ECU_PROXI_Data
        enable-take-address=true, indirect-api=false, port=DataServices_Data_22FD47_SoC_Temperature_0xFD47_Read
        enable-take-address=true, indirect-api=false, port=DataServices_Data_222013_VIN_Lock_State_Read
        enable-take-address=true, indirect-api=false, port=DataServices_Data_22F154_Hardware_Supplier_Identification
        enable-take-address=true, indirect-api=false, port=DataServices_Data_22442A_USS_Sensor_10_Part_Number_Read
        enable-take-address=true, indirect-api=false, port=DataServices_Data_22FD17_Magna_Production_HW_Version_information_Read
        enable-take-address=true, indirect-api=false, port=DataServices_Data_225104_FD_CAN14_Tx_Signals_Read
        enable-take-address=true, indirect-api=false, port=DataServices_Data_22FD07_OC_Result_Read
        enable-take-address=true, indirect-api=false, port=DataServices_Data_22F18C_ECU_Serial_Number
        enable-take-address=true, indirect-api=false, port=DataServices_Data_224421_USS_Sensor_1_Part_Number_Read
        enable-take-address=true, indirect-api=false, port=DataServices_Data_22FD46_Camera_Power_Supply_Read
        enable-take-address=true, indirect-api=false, port=DataServices_Data_22201F_Boot_Failure_Reason_Read
        enable-take-address=true, indirect-api=false, port=DataServices_Data_22F18B_FCA_ESLM_ECU_Software_Application_Number
        enable-take-address=true, indirect-api=false, port=DataServices_Data_22200A_Ignition_ON_Counter
        enable-take-address=true, indirect-api=false, port=DataServices_Data_22F10D_Diagnostic_Specification_Information
        enable-take-address=true, indirect-api=false, port=DataServices_Data_22F192_Supplier_ECU_Hardware_Part_Number
        enable-take-address=true, indirect-api=false, port=DataServices_Data_222026_CAN_Overrun_Counters
        enable-take-address=true, indirect-api=false, port=DataServices_Data_22F193_Supplier_ECU_Hardware_Version_Number
        enable-take-address=true, indirect-api=false, port=DataServices_Data_22F1A2_Vector_Delivery_ID
        enable-take-address=true, indirect-api=false, port=DataServices_Data_22FD0D_Left_Camera_Data_EEPROM_Read
        enable-take-address=true, indirect-api=false, port=DataServices_Data_225100_SPM_status_Read
        enable-take-address=true, indirect-api=false, port=DataServices_Data_22FD0C_Front_Camera_Data_EEPROM_Read
        enable-take-address=true, indirect-api=false, port=DataServices_Data_220103_VIN_Lock_Status
        enable-take-address=true, indirect-api=false, port=DataServices_Data_22FDF0_ECU_shutdown_process_Read
        enable-take-address=true, indirect-api=false, port=DataServices_Data_22191D_Time_of_Power_Latch
        enable-take-address=true, indirect-api=false, port=DataServices_Data_22FDF1_CPU_Load_Read
        enable-take-address=true, indirect-api=false, port=DataServices_Data_22F182_Application_Data_Identification
        enable-take-address=true, indirect-api=false, port=DataServices_Data_22442B_USS_Sensor_11_Part_Number_Read
        enable-take-address=true, indirect-api=false, port=DataServices_Data_2EF184_Application_Software_Fingerprint_writing_information
        enable-take-address=true, indirect-api=false, port=DataServices_Data_22F180_Boot_Software_Version_Information
        enable-take-address=true, indirect-api=false, port=DataServices_Data_22FD29_USS_Driving_Frequency_Read
        enable-take-address=true, indirect-api=false, port=DataServices_Data_22FD2A_USS_Ringing_Time_Read
        enable-take-address=true, indirect-api=false, port=DataServices_Data_221921_Operational_Mode_Status
        enable-take-address=true, indirect-api=false, port=DataServices_Data_225304_SPM_Event_Abort_2_Read
        enable-take-address=true, indirect-api=false, port=DataServices_Data_22F1A1_Configuration_Code
        enable-take-address=true, indirect-api=false, port=DataServices_Data_22F195_Supplier_ECU_Software_Version_Number
        enable-take-address=true, indirect-api=false, port=DataServices_Data_22FD16_Magna_Production_ICT_Data_Read
        enable-take-address=true, indirect-api=false, port=DataServices_Data_224429_USS_Sensor_9_Part_Number_Read
        enable-take-address=true, indirect-api=false, port=DataServices_Data_222010_Programming_Status
        enable-take-address=true, indirect-api=false, port=DataServices_Data_22F187_CODEP_ECU_Part_Number
        enable-take-address=true, indirect-api=false, port=DataServices_Data_2E2023_PROXI_Data
        enable-take-address=true, indirect-api=false, port=DataServices_Data_22FD49_SoC_Die_Temperature_ID_0xFD49_Read
        enable-take-address=true, indirect-api=false, port=DataServices_Data_22FD08_OC_Data_Read
        enable-take-address=true, indirect-api=false, port=DataServices_Data_22FD61_Vehicle_Variant_Coding_Data_Read
        enable-take-address=true, indirect-api=false, port=DataServices_Data_22FD33_Magna_Testing_2_Read
        enable-take-address=true, indirect-api=false, port=DataServices_Data_22F181_Application_Software_Identification
        enable-take-address=true, indirect-api=false, port=DataServices_Data_224427_USS_Sensor_7_Part_Number_Read
        enable-take-address=true, indirect-api=false, port=DataServices_Data_22F188_FCA_ESLM_ECU_Software_Number
        enable-take-address=true, indirect-api=false, port=DataServices_Data_22442C_USS_Sensor_12_Part_Number_Read
        enable-take-address=true, indirect-api=false, port=DataServices_Data_224426_USS_Sensor_6_Part_Number_Read
        enable-take-address=true, indirect-api=false, port=DataServices_Data_22F10B_ECU_Qualification
        enable-take-address=true, indirect-api=false, port=DataServices_Data_225201_Plant_Mode_Status_Read
        enable-take-address=true, indirect-api=false, port=DataServices_Data_222008_ECU_Life_Time_Not_Volatile_Memory
        enable-take-address=true, indirect-api=false, port=DataServices_Data_22F18A_FCA_ESLM_ECU_Software_Calibration_Number
        enable-take-address=true, indirect-api=false, port=DataServices_Data_224425_USS_Sensor_5_Part_Number_Read
        enable-take-address=true, indirect-api=false, port=DataServices_Data_22F122_Software_EBOM_Part_Number
        enable-take-address=true, indirect-api=false, port=DataServices_Data_225105_FD_CAN2_Tx_Signals_Read
        enable-take-address=true, indirect-api=false, port=DataServices_Data_22F1A0_System_Identification_Data
        enable-take-address=true, indirect-api=false, port=DataServices_Data_22FD0F_Right_Camera_Data_EEPROM_Read
        enable-take-address=true, indirect-api=false, port=DataServices_Data_224424_USS_Sensor_4_Part_Number_Read
        enable-take-address=true, indirect-api=false, port=DataServices_Data_221008_ECU_Life_Time
        enable-take-address=true, indirect-api=false, port=DataServices_Data_22F194_Supplier_ECU_Software_Part_Number
        enable-take-address=true, indirect-api=false, port=DataServices_Data_224423_USS_Sensor_3_Part_Number_Read
        enable-take-address=true, indirect-api=false, port=DataServices_Data_22FD2E_USS_Sensor_ID_Murata_SN_Read
        enable-take-address=true, indirect-api=false, port=DataServices_Data_22F1A6_Message_Matrix
        enable-take-address=true, indirect-api=false, port=DataServices_Data_222945_Flow_Control_Test
        enable-take-address=true, indirect-api=false, port=DataServices_Data_22F186_Active_Diagnostic_Session
        enable-take-address=true, indirect-api=false, port=Dcm_Read_Mode
        enable-take-address=true, indirect-api=false, port=RoutineServices_Routine_3101FE01_Calibration_Data_Reset_Start
        enable-take-address=true, indirect-api=false, port=RoutineServices_Routine_3101FE0E_Test_Pattern_Control_Start
        enable-take-address=true, indirect-api=false, port=RoutineServices_Routine_3101FF03_Test_Read_PMIC_Register_Start
        enable-take-address=true, indirect-api=false, port=DataServices_Data_22FD01_Previous_Camera_Calibration_Data
        enable-take-address=true, indirect-api=false, port=DataServices_Data_22FD60_ECU_Software_Status_Read
        enable-take-address=true, indirect-api=false, port=DataServices_Data_22FD14_FD14_Magna_Production_Date_Read
        enable-take-address=true, indirect-api=false, port=DataServices_Data_22FD38_Programmed_Assembly
        enable-take-address=true, indirect-api=false, port=DataServices_Data_22FD00_Plant_Camera_Calibration_Data
        enable-take-address=true, indirect-api=false, port=DataServices_Data_225305_SPM_Event_Abort_3_Read
        enable-take-address=true, indirect-api=false, port=DataServices_Data_22FD1D_PCB_Serial_Number
        enable-take-address=true, indirect-api=false, port=DataServices_Data_22FD13_Magna_Software_Version
        enable-take-address=true, indirect-api=false, port=RoutineServices_Routine_31011000_USS_Debug_Signals_Enable_Disable_Start
        enable-take-address=true, indirect-api=false, port=RoutineServices_Routine_31013000_XCP_Enable_Disable_Start
        enable-take-address=true, indirect-api=false, port=DataServices_Data_22F111_Public_Certificates_Regional_Support_Read
        enable-take-address=true, indirect-api=false, port=DataServices_Data_222032_Secure_Log_Read
        enable-take-address=true, indirect-api=false, port=DataServices_Data_222959_Hosted_App_Firmware_Cal_Config_Data_Header_Info_Read
        enable-take-address=true, indirect-api=false, port=DataServices_Data_22100C_Security_Status_Read
        enable-take-address=true, indirect-api=false, port=DataServices_Data_222954_Policy_Type_Read
        enable-take-address=true, indirect-api=false, port=DataServices_Data_222030_Authenticated_Diagnostic_Previous_Access_Read
        enable-take-address=true, indirect-api=false, port=DataServices_Data_2EFD4E_Reset_NVM_Write
        enable-take-address=true, indirect-api=false, port=DataServices_Data_22FD64_ASIL_B_Fault_Status_Read
        enable-take-address=true, indirect-api=false, port=DataServices_Data_220108_Authenticated_Diagnostics_Active_Role_Read
        enable-take-address=true, indirect-api=false, port=DataServices_Data_22295F_DCL_and_Cerstore_Header_Info_Read
        enable-take-address=true, indirect-api=false, port=DataServices_Data_222031_Disallowed_Certificate_List_Read
        enable-take-address=true, indirect-api=false, port=DataServices_Data_22295A_Hosted_App_Firmware_Cal_Config_Data_Header_UUID_Read
        enable-take-address=true, indirect-api=false, port=DataServices_Data_222958_Hosted_App_firmware_Header_UUID_Read
        enable-take-address=true, indirect-api=false, port=DataServices_Data_222957_Hosted_App_Firmware_Header_Info_Read
        enable-take-address=true, indirect-api=false, port=DataServices_Data_22FD62_ASIL_QM_Fault_Status_Read
        enable-take-address=true, indirect-api=false, port=DataServices_Data_22FD86_Functional_Settings_Read
        enable-take-address=true, indirect-api=false, port=DataServices_Data_225109_Rear_Sensor_HealthBlockage_LiveDetection_Check_Read
        enable-take-address=true, indirect-api=false, port=DataServices_Data_225107_Front_Sensor_HealthBlockage_LiveDetection_Check_Read
        enable-take-address=true, indirect-api=false, port=DataServices_Data_22FD4A_Ultrasonic_Sensors_Power_supply_and_Current_Level_Read
        enable-take-address=true, indirect-api=false, port=DataServices_Data_22FD65_FuSa_Module_Status_Read
        enable-take-address=true, indirect-api=false, port=DataServices_Data_222951_Certificate_Store_UUID_Read
        enable-take-address=true, indirect-api=false, port=DataServices_Data_22FD66_Camera_occlusion_and_low_light_status_Read
        enable-take-address=true, indirect-api=false, port=DataServices_Data_22FD67_Camera_DLD_Status_Read
        enable-take-address=true, indirect-api=false, port=DataServices_Data_22295B_HTA_Header_Info_Read
        enable-take-address=true, indirect-api=false, port=DataServices_Data_22FD43_Active_Safe_State_Read
        enable-take-address=true, indirect-api=false, port=DataServices_Data_22FD44_Error_Flags_Read
        enable-take-address=true, indirect-api=false, port=DataServices_Data_22295E_DCL_Header_UUID_Read
        enable-take-address=true, indirect-api=false, port=DataServices_Data_22295C_HTA_Header_UUID_Read
        enable-take-address=true, indirect-api=false, port=DataServices_Data_22FD74_PHY_Tunning_Error_And_Buffer_Mark_Error_Read
        enable-take-address=true, indirect-api=false, port=RoutineServices_Routine_31015502_TRSC_Trailer_Calibration_Memory_Clear_Start
        enable-take-address=true, indirect-api=false, port=DataServices_Data_22FDF7_Intrinsic_Camera_NvM_Data_Read
        enable-take-address=true, indirect-api=false, port=DataServices_Data_22FDF6_RunTimeStatsData_Read
        enable-take-address=true, indirect-api=false, port=DataServices_Data_22FD04_USS_Sensor_tuning_values_Read
        enable-take-address=true, indirect-api=false, port=Dcm_Read_ModeProgPreconditionCheck
        enable-take-address=true, indirect-api=false, port=DataServices_Data_22FDF8_StackUsage_Read
        enable-take-address=true, indirect-api=false, port=DataServices_Data_22FDF5_PerformanceStatEnable_Read
      7 x runnable:
        Dcm_MainFunction: mode-access-points=[Dcm_Read_Mode.Dcm_Read_Mode, Dcm_Read_ModeProgPreconditionCheck.Dcm_Read_ModeProgPreconditionCheck]
          4 x mode switch point:
            ModeSwitchPointDcm_MainFunction_DcmControlDtcSetting_DcmControlDtcSetting: mode-group=DcmControlDtcSetting.DcmControlDtcSetting
            ModeSwitchPointDcm_MainFunction_DcmEcuReset_DcmEcuReset: mode-group=DcmEcuReset.DcmEcuReset
            ModeSwitchPointDcm_MainFunction_DcmDiagnosticSessionControl_DcmDiagnosticSessionControl: mode-group=DcmDiagnosticSessionControl.DcmDiagnosticSessionControl
            ModeSwitchPointDcm_MainFunction_DcmCommunicationControl_ComMConf_ComMChannel_CN_FDCAN2_28a8fc44_DcmCommunicationControl_9ad05e00: mode-group=DcmCommunicationControl_ComMConf_ComMChannel_CN_FDCAN2_28a8fc44.DcmCommunicationControl_ComMConf_ComMChannel_CN_FDCAN2_28a8fc44
          206 x sync call, all with timeout=0:
            OpServerCallDcm_MainFunction_Start_RoutineServices_Routine_31012000_Original_VIN_Lock: operation=RoutineServices_Routine_31012000_Original_VIN_Lock.Start
            OpServerCallDcm_MainFunction_Start_RoutineServices_Routine_31012001_Original_VIN_Unlock: operation=RoutineServices_Routine_31012001_Original_VIN_Unlock.Start
            OpServerCallDcm_MainFunction_Start_RoutineServices_Routine_31015000_Park_Assist_ON_OFF_State_Start: operation=RoutineServices_Routine_31015000_Park_Assist_ON_OFF_State_Start.Start
            OpServerCallDcm_MainFunction_Start_RoutineServices_Routine_31015101_Sensor_Functional_Test_Start: operation=RoutineServices_Routine_31015101_Sensor_Functional_Test_Start.Start
            OpServerCallDcm_MainFunction_Start_RoutineServices_Routine_31015200_Plant_Mode_Routine_Start: operation=RoutineServices_Routine_31015200_Plant_Mode_Routine_Start.Start
            OpServerCallDcm_MainFunction_RequestResults_RoutineServices_Routine_31015200_Plant_Mode_Routine_Start: operation=RoutineServices_Routine_31015200_Plant_Mode_Routine_Start.RequestResults
            OpServerCallDcm_MainFunction_Start_RoutineServices_Routine_31015400_Camera_EOL_Calibration_Start: operation=RoutineServices_Routine_31015400_Camera_EOL_Calibration_Start.Start
            OpServerCallDcm_MainFunction_RequestResults_RoutineServices_Routine_31015400_Camera_EOL_Calibration_Start: operation=RoutineServices_Routine_31015400_Camera_EOL_Calibration_Start.RequestResults
            OpServerCallDcm_MainFunction_Start_RoutineServices_Routine_31015401_Camera_Service_Calibration_Start: operation=RoutineServices_Routine_31015401_Camera_Service_Calibration_Start.Start
            OpServerCallDcm_MainFunction_RequestResults_RoutineServices_Routine_31015401_Camera_Service_Calibration_Start: operation=RoutineServices_Routine_31015401_Camera_Service_Calibration_Start.RequestResults
            OpServerCallDcm_MainFunction_Start_RoutineServices_Routine_3101D001_Disable_Fail_safe_reaction_Start: operation=RoutineServices_Routine_3101D001_Disable_Fail_safe_reaction_Start.Start
            OpServerCallDcm_MainFunction_Stop_RoutineServices_Routine_3101D001_Disable_Fail_safe_reaction_Start: operation=RoutineServices_Routine_3101D001_Disable_Fail_safe_reaction_Start.Stop
            OpServerCallDcm_MainFunction_Start_RoutineServices_Routine_3101D002_Check_Programming_Preconditions_Start: operation=RoutineServices_Routine_3101D002_Check_Programming_Preconditions_Start.Start
            OpServerCallDcm_MainFunction_Start_RoutineServices_Routine_3101D003_Application_Logical_Block_Hash: operation=RoutineServices_Routine_3101D003_Application_Logical_Block_Hash.Start
            OpServerCallDcm_MainFunction_Start_RoutineServices_Routine_3101F000_Check_Program_Start: operation=RoutineServices_Routine_3101F000_Check_Program_Start.Start
            OpServerCallDcm_MainFunction_Start_RoutineServices_Routine_3101FE02_Test_Write_PMIC_Register_Start: operation=RoutineServices_Routine_3101FE02_Test_Write_PMIC_Register_Start.Start
            OpServerCallDcm_MainFunction_Start_RoutineServices_Routine_3101FF00_FlashErase_Start: operation=RoutineServices_Routine_3101FF00_FlashErase_Start.Start
            OpServerCallDcm_MainFunction_Start_RoutineServices_Routine_3101FF01_checkProgrammingDependencies_FlashChecksum_Start: operation=RoutineServices_Routine_3101FF01_checkProgrammingDependencies_FlashChecksum_Start.Start
            OpServerCallDcm_MainFunction_ReadData_DataServices_Data_225103_FD_CAN2_Rx_Signals_Read: operation=DataServices_Data_225103_FD_CAN2_Rx_Signals_Read.ReadData
            OpServerCallDcm_MainFunction_ReadData_DataServices_Data_22FD1E_Calibration_Status_Read: operation=DataServices_Data_22FD1E_Calibration_Status_Read.ReadData
            OpServerCallDcm_MainFunction_ReadData_DataServices_Data_220107_RoE_Activation_State: operation=DataServices_Data_220107_RoE_Activation_State.ReadData
            OpServerCallDcm_MainFunction_WriteData_DataServices_Data_220107_RoE_Activation_State: operation=DataServices_Data_220107_RoE_Activation_State.WriteData
            OpServerCallDcm_MainFunction_ReadData_DataServices_Data_22FD1C_Current_Camera_Calibration_Data_Read: operation=DataServices_Data_22FD1C_Current_Camera_Calibration_Data_Read.ReadData
            OpServerCallDcm_MainFunction_ReadData_DataServices_Data_22102A_Check_EOL_Configuration_Data: operation=DataServices_Data_22102A_Check_EOL_Configuration_Data.ReadData
            OpServerCallDcm_MainFunction_WriteData_DataServices_Data_2EF185_Application_Data_Software_Fingerprint_Writing_Information: operation=DataServices_Data_2EF185_Application_Data_Software_Fingerprint_Writing_Information.WriteData
            OpServerCallDcm_MainFunction_ReadData_DataServices_Data_222001_Odometer: operation=DataServices_Data_222001_Odometer.ReadData
            OpServerCallDcm_MainFunction_ReadData_DataServices_Data_22F191_FCA_ESLM_ECU_Hardware_Number: operation=DataServices_Data_22F191_FCA_ESLM_ECU_Hardware_Number.ReadData
            OpServerCallDcm_MainFunction_ReadData_DataServices_Data_225303_SPM_Event_Abort_1_Read: operation=DataServices_Data_225303_SPM_Event_Abort_1_Read.ReadData
            OpServerCallDcm_MainFunction_ReadData_DataServices_Data_22100B_Diagnostic_Tool_and_Session_Status: operation=DataServices_Data_22100B_Diagnostic_Tool_and_Session_Status.ReadData
            OpServerCallDcm_MainFunction_ReadData_DataServices_Data_222002_Odometer_at_last_Flash_programming: operation=DataServices_Data_222002_Odometer_at_last_Flash_programming.ReadData
            OpServerCallDcm_MainFunction_ReadData_DataServices_Data_22FD48_PCBA_Temperature_Read: operation=DataServices_Data_22FD48_PCBA_Temperature_Read.ReadData
            OpServerCallDcm_MainFunction_ReadData_DataServices_Data_22FD0E_Rear_Camera_Data_EEPROM_Read: operation=DataServices_Data_22FD0E_Rear_Camera_Data_EEPROM_Read.ReadData
            OpServerCallDcm_MainFunction_ReadData_DataServices_Data_22FDF2_Reset_Reason_Read: operation=DataServices_Data_22FDF2_Reset_Reason_Read.ReadData
            OpServerCallDcm_MainFunction_ReadData_DataServices_Data_224422_USS_Sensor2_Part_Number_Read: operation=DataServices_Data_224422_USS_Sensor2_Part_Number_Read.ReadData
            OpServerCallDcm_MainFunction_ReadData_DataServices_Data_22F1B5_Application_Data_Software_Fingerprint_Reading_Information: operation=DataServices_Data_22F1B5_Application_Data_Software_Fingerprint_Reading_Information.ReadData
            OpServerCallDcm_MainFunction_ReadData_DataServices_Data_224428_USS_Sensor_8_Part_Number_Read: operation=DataServices_Data_224428_USS_Sensor_8_Part_Number_Read.ReadData
            OpServerCallDcm_MainFunction_ReadData_DataServices_Data_221004_Battery_Voltage: operation=DataServices_Data_221004_Battery_Voltage.ReadData
            OpServerCallDcm_MainFunction_ReadData_DataServices_Data_22200B_Time_First_DTC_Detection: operation=DataServices_Data_22200B_Time_First_DTC_Detection.ReadData
            OpServerCallDcm_MainFunction_ReadData_DataServices_Data_22F133_EBOM_Assembly_Part_Number: operation=DataServices_Data_22F133_EBOM_Assembly_Part_Number.ReadData
            OpServerCallDcm_MainFunction_ReadData_DataServices_Data_22FD20_ECU_PinStates_Read: operation=DataServices_Data_22FD20_ECU_PinStates_Read.ReadData
            OpServerCallDcm_MainFunction_ReadData_DataServices_Data_22F112_PTESLM_Hardware_Number: operation=DataServices_Data_22F112_PTESLM_Hardware_Number.ReadData
            OpServerCallDcm_MainFunction_ReadData_DataServices_Data_222939_FDCAN2_BUS_Network_WakeUp_Reason: operation=DataServices_Data_222939_FDCAN2_BUS_Network_WakeUp_Reason.ReadData
            OpServerCallDcm_MainFunction_ReadData_DataServices_Data_22FD0A_SC_Data_Read: operation=DataServices_Data_22FD0A_SC_Data_Read.ReadData
            OpServerCallDcm_MainFunction_WriteData_DataServices_Data_22FD0A_SC_Data_Read: operation=DataServices_Data_22FD0A_SC_Data_Read.WriteData
            OpServerCallDcm_MainFunction_ReadData_DataServices_Data_221009_ECU_Time_Since_Ignition_ON: operation=DataServices_Data_221009_ECU_Time_Since_Ignition_ON.ReadData
            OpServerCallDcm_MainFunction_ReadData_DataServices_Data_22FD2B_USS_Direct_Distance_0xFD2B_Read: operation=DataServices_Data_22FD2B_USS_Direct_Distance_0xFD2B_Read.ReadData
            OpServerCallDcm_MainFunction_ReadData_DataServices_Data_22292E_PROXI_Write_Counter: operation=DataServices_Data_22292E_PROXI_Write_Counter.ReadData
            OpServerCallDcm_MainFunction_ReadData_DataServices_Data_221002_Vehicle_Speed: operation=DataServices_Data_221002_Vehicle_Speed.ReadData
            OpServerCallDcm_MainFunction_ReadData_DataServices_Data_225500_Trailer_Sense_and_Drive_Function_Data_Read: operation=DataServices_Data_225500_Trailer_Sense_and_Drive_Function_Data_Read.ReadData
            OpServerCallDcm_MainFunction_ReadData_DataServices_Data_22F190_VIN_Original: operation=DataServices_Data_22F190_VIN_Original.ReadData
            OpServerCallDcm_MainFunction_ReadData_DataServices_Data_22FD42_Failsafe_Behaviour_Read: operation=DataServices_Data_22FD42_Failsafe_Behaviour_Read.ReadData
            OpServerCallDcm_MainFunction_WriteData_DataServices_Data_22FD42_Failsafe_Behaviour_Read: operation=DataServices_Data_22FD42_Failsafe_Behaviour_Read.WriteData
            OpServerCallDcm_MainFunction_ReadData_DataServices_Data_225302_Rear_Braking_Event_3_Read: operation=DataServices_Data_225302_Rear_Braking_Event_3_Read.ReadData
            OpServerCallDcm_MainFunction_ReadData_DataServices_Data_225300_Rear_Braking_Event_1_Read: operation=DataServices_Data_225300_Rear_Braking_Event_1_Read.ReadData
            OpServerCallDcm_MainFunction_ReadData_DataServices_Data_22FD2C_USS_Temperature_Read: operation=DataServices_Data_22FD2C_USS_Temperature_Read.ReadData
            OpServerCallDcm_MainFunction_ReadData_DataServices_Data_222003_Boot_Software_Programming_Attempt_Counter: operation=DataServices_Data_222003_Boot_Software_Programming_Attempt_Counter.ReadData
            OpServerCallDcm_MainFunction_ReadData_DataServices_Data_225501_Trailer_coupler_sense_detection_Function_Data_Read: operation=DataServices_Data_225501_Trailer_coupler_sense_detection_Function_Data_Read.ReadData
            OpServerCallDcm_MainFunction_ReadData_DataServices_Data_22F132_EBOM_ECU_Part_Number: operation=DataServices_Data_22F132_EBOM_ECU_Part_Number.ReadData
            OpServerCallDcm_MainFunction_ReadData_DataServices_Data_22F1B3_Boot_Software_Fingerprint_Reading_Information: operation=DataServices_Data_22F1B3_Boot_Software_Fingerprint_Reading_Information.ReadData
            OpServerCallDcm_MainFunction_ReadData_DataServices_Data_2F5001_Gear_Position_Read: operation=DataServices_Data_2F5001_Gear_Position_Read.ReadData
            OpServerCallDcm_MainFunction_ReturnControlToECU_DataServices_Data_2F5001_Gear_Position_Read: operation=DataServices_Data_2F5001_Gear_Position_Read.ReturnControlToECU
            OpServerCallDcm_MainFunction_ShortTermAdjustment_DataServices_Data_2F5001_Gear_Position_Read: operation=DataServices_Data_2F5001_Gear_Position_Read.ShortTermAdjustment
            OpServerCallDcm_MainFunction_ReadData_DataServices_Data_22F1B4_Application_Software_Fingerprint_Reading_Information: operation=DataServices_Data_22F1B4_Application_Software_Fingerprint_Reading_Information.ReadData
            OpServerCallDcm_MainFunction_ReadData_DataServices_Data_22FD28_USS_Ringing_Frequency_Read: operation=DataServices_Data_22FD28_USS_Ringing_Frequency_Read.ReadData
            OpServerCallDcm_MainFunction_ReadData_DataServices_Data_22200D_Odometer_Last_Clear_Data_Trouble_Code_DTC: operation=DataServices_Data_22200D_Odometer_Last_Clear_Data_Trouble_Code_DTC.ReadData
            OpServerCallDcm_MainFunction_ReadData_DataServices_Data_22FD2D_USS_Sensor_ID_IME_SN_Read: operation=DataServices_Data_22FD2D_USS_Sensor_ID_IME_SN_Read.ReadData
            OpServerCallDcm_MainFunction_ReadData_DataServices_Data_22F134_CODEP_assembly_part_number: operation=DataServices_Data_22F134_CODEP_assembly_part_number.ReadData
            OpServerCallDcm_MainFunction_ReadData_DataServices_Data_225301_Rear_Braking_Event_2_Read: operation=DataServices_Data_225301_Rear_Braking_Event_2_Read.ReadData
            OpServerCallDcm_MainFunction_ReadData_DataServices_Data_22201A_Application_Software_Programming_Attempt_Counter: operation=DataServices_Data_22201A_Application_Software_Programming_Attempt_Counter.ReadData
            OpServerCallDcm_MainFunction_ReadData_DataServices_Data_225102_FD_CAN14_Rx_Signals_Read: operation=DataServices_Data_225102_FD_CAN14_Rx_Signals_Read.ReadData
            OpServerCallDcm_MainFunction_ReadData_DataServices_Data_22F1B0_VIN_Current: operation=DataServices_Data_22F1B0_VIN_Current.ReadData
            OpServerCallDcm_MainFunction_ReadData_DataServices_Data_22FD15_Magna_Production_HW_Number_Read: operation=DataServices_Data_22FD15_Magna_Production_HW_Number_Read.ReadData
            OpServerCallDcm_MainFunction_ReadData_DataServices_Data_22201B_Application_Data_Software_Programming_Attempt_Counter: operation=DataServices_Data_22201B_Application_Data_Software_Programming_Attempt_Counter.ReadData
            OpServerCallDcm_MainFunction_ReadData_DataServices_Data_22200C_Time_Since_Ignition_ON_of_first_DTC_Detection: operation=DataServices_Data_22200C_Time_Since_Ignition_ON_of_first_DTC_Detection.ReadData
            OpServerCallDcm_MainFunction_ReadData_DataServices_Data_22FD31_Magna_EOL_Coding_State_Read: operation=DataServices_Data_22FD31_Magna_EOL_Coding_State_Read.ReadData
            OpServerCallDcm_MainFunction_WriteData_DataServices_Data_22FD31_Magna_EOL_Coding_State_Read: operation=DataServices_Data_22FD31_Magna_EOL_Coding_State_Read.WriteData
            OpServerCallDcm_MainFunction_ReadData_DataServices_Data_224451_EOL_Calibration_State_Read: operation=DataServices_Data_224451_EOL_Calibration_State_Read.ReadData
            OpServerCallDcm_MainFunction_ReadData_DataServices_Data_22F155_Software_Supplier_Identification: operation=DataServices_Data_22F155_Software_Supplier_Identification.ReadData
            OpServerCallDcm_MainFunction_ReadData_DataServices_Data_22F110_ECU_Diagnostic_Identification: operation=DataServices_Data_22F110_ECU_Diagnostic_Identification.ReadData
            OpServerCallDcm_MainFunction_ReadData_DataServices_Data_222024_Read_ECU_PROXI_Data: operation=DataServices_Data_222024_Read_ECU_PROXI_Data.ReadData
            OpServerCallDcm_MainFunction_ReadDataLength_DataServices_Data_222024_Read_ECU_PROXI_Data: operation=DataServices_Data_222024_Read_ECU_PROXI_Data.ReadDataLength
            OpServerCallDcm_MainFunction_ReadData_DataServices_Data_22FD47_SoC_Temperature_0xFD47_Read: operation=DataServices_Data_22FD47_SoC_Temperature_0xFD47_Read.ReadData
            OpServerCallDcm_MainFunction_ReadData_DataServices_Data_222013_VIN_Lock_State_Read: operation=DataServices_Data_222013_VIN_Lock_State_Read.ReadData
            OpServerCallDcm_MainFunction_ReadData_DataServices_Data_22F154_Hardware_Supplier_Identification: operation=DataServices_Data_22F154_Hardware_Supplier_Identification.ReadData
            OpServerCallDcm_MainFunction_ReadData_DataServices_Data_22442A_USS_Sensor_10_Part_Number_Read: operation=DataServices_Data_22442A_USS_Sensor_10_Part_Number_Read.ReadData
            OpServerCallDcm_MainFunction_ReadData_DataServices_Data_22FD17_Magna_Production_HW_Version_information_Read: operation=DataServices_Data_22FD17_Magna_Production_HW_Version_information_Read.ReadData
            OpServerCallDcm_MainFunction_ReadData_DataServices_Data_225104_FD_CAN14_Tx_Signals_Read: operation=DataServices_Data_225104_FD_CAN14_Tx_Signals_Read.ReadData
            OpServerCallDcm_MainFunction_ReadData_DataServices_Data_22FD07_OC_Result_Read: operation=DataServices_Data_22FD07_OC_Result_Read.ReadData
            OpServerCallDcm_MainFunction_ReadData_DataServices_Data_22F18C_ECU_Serial_Number: operation=DataServices_Data_22F18C_ECU_Serial_Number.ReadData
            OpServerCallDcm_MainFunction_ReadData_DataServices_Data_224421_USS_Sensor_1_Part_Number_Read: operation=DataServices_Data_224421_USS_Sensor_1_Part_Number_Read.ReadData
            OpServerCallDcm_MainFunction_ReadData_DataServices_Data_22FD46_Camera_Power_Supply_Read: operation=DataServices_Data_22FD46_Camera_Power_Supply_Read.ReadData
            OpServerCallDcm_MainFunction_ReadData_DataServices_Data_22201F_Boot_Failure_Reason_Read: operation=DataServices_Data_22201F_Boot_Failure_Reason_Read.ReadData
            OpServerCallDcm_MainFunction_ReadData_DataServices_Data_22F18B_FCA_ESLM_ECU_Software_Application_Number: operation=DataServices_Data_22F18B_FCA_ESLM_ECU_Software_Application_Number.ReadData
            OpServerCallDcm_MainFunction_ReadData_DataServices_Data_22200A_Ignition_ON_Counter: operation=DataServices_Data_22200A_Ignition_ON_Counter.ReadData
            OpServerCallDcm_MainFunction_ReadData_DataServices_Data_22F10D_Diagnostic_Specification_Information: operation=DataServices_Data_22F10D_Diagnostic_Specification_Information.ReadData
            OpServerCallDcm_MainFunction_ReadData_DataServices_Data_22F192_Supplier_ECU_Hardware_Part_Number: operation=DataServices_Data_22F192_Supplier_ECU_Hardware_Part_Number.ReadData
            OpServerCallDcm_MainFunction_ReadData_DataServices_Data_222026_CAN_Overrun_Counters: operation=DataServices_Data_222026_CAN_Overrun_Counters.ReadData
            OpServerCallDcm_MainFunction_ReadData_DataServices_Data_22F193_Supplier_ECU_Hardware_Version_Number: operation=DataServices_Data_22F193_Supplier_ECU_Hardware_Version_Number.ReadData
            OpServerCallDcm_MainFunction_ReadData_DataServices_Data_22F1A2_Vector_Delivery_ID: operation=DataServices_Data_22F1A2_Vector_Delivery_ID.ReadData
            OpServerCallDcm_MainFunction_ReadData_DataServices_Data_22FD0D_Left_Camera_Data_EEPROM_Read: operation=DataServices_Data_22FD0D_Left_Camera_Data_EEPROM_Read.ReadData
            OpServerCallDcm_MainFunction_ReadData_DataServices_Data_225100_SPM_status_Read: operation=DataServices_Data_225100_SPM_status_Read.ReadData
            OpServerCallDcm_MainFunction_ReadData_DataServices_Data_22FD0C_Front_Camera_Data_EEPROM_Read: operation=DataServices_Data_22FD0C_Front_Camera_Data_EEPROM_Read.ReadData
            OpServerCallDcm_MainFunction_ReadData_DataServices_Data_220103_VIN_Lock_Status: operation=DataServices_Data_220103_VIN_Lock_Status.ReadData
            OpServerCallDcm_MainFunction_ReadData_DataServices_Data_22FDF0_ECU_shutdown_process_Read: operation=DataServices_Data_22FDF0_ECU_shutdown_process_Read.ReadData
            OpServerCallDcm_MainFunction_WriteData_DataServices_Data_22FDF0_ECU_shutdown_process_Read: operation=DataServices_Data_22FDF0_ECU_shutdown_process_Read.WriteData
            OpServerCallDcm_MainFunction_ReadData_DataServices_Data_22191D_Time_of_Power_Latch: operation=DataServices_Data_22191D_Time_of_Power_Latch.ReadData
            OpServerCallDcm_MainFunction_ReadData_DataServices_Data_22FDF1_CPU_Load_Read: operation=DataServices_Data_22FDF1_CPU_Load_Read.ReadData
            OpServerCallDcm_MainFunction_ReadData_DataServices_Data_22F182_Application_Data_Identification: operation=DataServices_Data_22F182_Application_Data_Identification.ReadData
            OpServerCallDcm_MainFunction_ReadData_DataServices_Data_22442B_USS_Sensor_11_Part_Number_Read: operation=DataServices_Data_22442B_USS_Sensor_11_Part_Number_Read.ReadData
            OpServerCallDcm_MainFunction_WriteData_DataServices_Data_2EF184_Application_Software_Fingerprint_writing_information: operation=DataServices_Data_2EF184_Application_Software_Fingerprint_writing_information.WriteData
            OpServerCallDcm_MainFunction_ReadData_DataServices_Data_22F180_Boot_Software_Version_Information: operation=DataServices_Data_22F180_Boot_Software_Version_Information.ReadData
            OpServerCallDcm_MainFunction_ReadData_DataServices_Data_22FD29_USS_Driving_Frequency_Read: operation=DataServices_Data_22FD29_USS_Driving_Frequency_Read.ReadData
            OpServerCallDcm_MainFunction_ReadData_DataServices_Data_22FD2A_USS_Ringing_Time_Read: operation=DataServices_Data_22FD2A_USS_Ringing_Time_Read.ReadData
            OpServerCallDcm_MainFunction_ReadData_DataServices_Data_221921_Operational_Mode_Status: operation=DataServices_Data_221921_Operational_Mode_Status.ReadData
            OpServerCallDcm_MainFunction_ReadData_DataServices_Data_225304_SPM_Event_Abort_2_Read: operation=DataServices_Data_225304_SPM_Event_Abort_2_Read.ReadData
            OpServerCallDcm_MainFunction_ReadData_DataServices_Data_22F1A1_Configuration_Code: operation=DataServices_Data_22F1A1_Configuration_Code.ReadData
            OpServerCallDcm_MainFunction_ReadData_DataServices_Data_22F195_Supplier_ECU_Software_Version_Number: operation=DataServices_Data_22F195_Supplier_ECU_Software_Version_Number.ReadData
            OpServerCallDcm_MainFunction_ReadData_DataServices_Data_22FD16_Magna_Production_ICT_Data_Read: operation=DataServices_Data_22FD16_Magna_Production_ICT_Data_Read.ReadData
            OpServerCallDcm_MainFunction_ReadData_DataServices_Data_224429_USS_Sensor_9_Part_Number_Read: operation=DataServices_Data_224429_USS_Sensor_9_Part_Number_Read.ReadData
            OpServerCallDcm_MainFunction_ReadData_DataServices_Data_222010_Programming_Status: operation=DataServices_Data_222010_Programming_Status.ReadData
            OpServerCallDcm_MainFunction_ReadData_DataServices_Data_22F187_CODEP_ECU_Part_Number: operation=DataServices_Data_22F187_CODEP_ECU_Part_Number.ReadData
            OpServerCallDcm_MainFunction_WriteData_DataServices_Data_2E2023_PROXI_Data: operation=DataServices_Data_2E2023_PROXI_Data.WriteData
            OpServerCallDcm_MainFunction_ReadData_DataServices_Data_22FD49_SoC_Die_Temperature_ID_0xFD49_Read: operation=DataServices_Data_22FD49_SoC_Die_Temperature_ID_0xFD49_Read.ReadData
            OpServerCallDcm_MainFunction_ReadData_DataServices_Data_22FD08_OC_Data_Read: operation=DataServices_Data_22FD08_OC_Data_Read.ReadData
            OpServerCallDcm_MainFunction_WriteData_DataServices_Data_22FD08_OC_Data_Read: operation=DataServices_Data_22FD08_OC_Data_Read.WriteData
            OpServerCallDcm_MainFunction_ReadData_DataServices_Data_22FD61_Vehicle_Variant_Coding_Data_Read: operation=DataServices_Data_22FD61_Vehicle_Variant_Coding_Data_Read.ReadData
            OpServerCallDcm_MainFunction_ReadData_DataServices_Data_22FD33_Magna_Testing_2_Read: operation=DataServices_Data_22FD33_Magna_Testing_2_Read.ReadData
            OpServerCallDcm_MainFunction_WriteData_DataServices_Data_22FD33_Magna_Testing_2_Read: operation=DataServices_Data_22FD33_Magna_Testing_2_Read.WriteData
            OpServerCallDcm_MainFunction_ReadData_DataServices_Data_22F181_Application_Software_Identification: operation=DataServices_Data_22F181_Application_Software_Identification.ReadData
            OpServerCallDcm_MainFunction_ReadData_DataServices_Data_224427_USS_Sensor_7_Part_Number_Read: operation=DataServices_Data_224427_USS_Sensor_7_Part_Number_Read.ReadData
            OpServerCallDcm_MainFunction_ReadData_DataServices_Data_22F188_FCA_ESLM_ECU_Software_Number: operation=DataServices_Data_22F188_FCA_ESLM_ECU_Software_Number.ReadData
            OpServerCallDcm_MainFunction_ReadData_DataServices_Data_22442C_USS_Sensor_12_Part_Number_Read: operation=DataServices_Data_22442C_USS_Sensor_12_Part_Number_Read.ReadData
            OpServerCallDcm_MainFunction_ReadData_DataServices_Data_224426_USS_Sensor_6_Part_Number_Read: operation=DataServices_Data_224426_USS_Sensor_6_Part_Number_Read.ReadData
            OpServerCallDcm_MainFunction_ReadData_DataServices_Data_22F10B_ECU_Qualification: operation=DataServices_Data_22F10B_ECU_Qualification.ReadData
            OpServerCallDcm_MainFunction_ReadData_DataServices_Data_225201_Plant_Mode_Status_Read: operation=DataServices_Data_225201_Plant_Mode_Status_Read.ReadData
            OpServerCallDcm_MainFunction_ReadData_DataServices_Data_222008_ECU_Life_Time_Not_Volatile_Memory: operation=DataServices_Data_222008_ECU_Life_Time_Not_Volatile_Memory.ReadData
            OpServerCallDcm_MainFunction_ReadData_DataServices_Data_22F18A_FCA_ESLM_ECU_Software_Calibration_Number: operation=DataServices_Data_22F18A_FCA_ESLM_ECU_Software_Calibration_Number.ReadData
            OpServerCallDcm_MainFunction_ReadData_DataServices_Data_224425_USS_Sensor_5_Part_Number_Read: operation=DataServices_Data_224425_USS_Sensor_5_Part_Number_Read.ReadData
            OpServerCallDcm_MainFunction_ReadData_DataServices_Data_22F122_Software_EBOM_Part_Number: operation=DataServices_Data_22F122_Software_EBOM_Part_Number.ReadData
            OpServerCallDcm_MainFunction_ReadData_DataServices_Data_225105_FD_CAN2_Tx_Signals_Read: operation=DataServices_Data_225105_FD_CAN2_Tx_Signals_Read.ReadData
            OpServerCallDcm_MainFunction_ReadData_DataServices_Data_22F1A0_System_Identification_Data: operation=DataServices_Data_22F1A0_System_Identification_Data.ReadData
            OpServerCallDcm_MainFunction_ReadData_DataServices_Data_22FD0F_Right_Camera_Data_EEPROM_Read: operation=DataServices_Data_22FD0F_Right_Camera_Data_EEPROM_Read.ReadData
            OpServerCallDcm_MainFunction_ReadData_DataServices_Data_224424_USS_Sensor_4_Part_Number_Read: operation=DataServices_Data_224424_USS_Sensor_4_Part_Number_Read.ReadData
            OpServerCallDcm_MainFunction_ReadData_DataServices_Data_221008_ECU_Life_Time: operation=DataServices_Data_221008_ECU_Life_Time.ReadData
            OpServerCallDcm_MainFunction_ReadData_DataServices_Data_22F194_Supplier_ECU_Software_Part_Number: operation=DataServices_Data_22F194_Supplier_ECU_Software_Part_Number.ReadData
            OpServerCallDcm_MainFunction_ReadData_DataServices_Data_224423_USS_Sensor_3_Part_Number_Read: operation=DataServices_Data_224423_USS_Sensor_3_Part_Number_Read.ReadData
            OpServerCallDcm_MainFunction_ReadData_DataServices_Data_22FD2E_USS_Sensor_ID_Murata_SN_Read: operation=DataServices_Data_22FD2E_USS_Sensor_ID_Murata_SN_Read.ReadData
            OpServerCallDcm_MainFunction_ReadData_DataServices_Data_22F1A6_Message_Matrix: operation=DataServices_Data_22F1A6_Message_Matrix.ReadData
            OpServerCallDcm_MainFunction_ReadData_DataServices_Data_222945_Flow_Control_Test: operation=DataServices_Data_222945_Flow_Control_Test.ReadData
            OpServerCallDcm_MainFunction_WriteData_DataServices_Data_222945_Flow_Control_Test: operation=DataServices_Data_222945_Flow_Control_Test.WriteData
            OpServerCallDcm_MainFunction_ReadData_DataServices_Data_22F186_Active_Diagnostic_Session: operation=DataServices_Data_22F186_Active_Diagnostic_Session.ReadData
            OpServerCallDcm_MainFunction_Start_RoutineServices_Routine_3101FE01_Calibration_Data_Reset_Start: operation=RoutineServices_Routine_3101FE01_Calibration_Data_Reset_Start.Start
            OpServerCallDcm_MainFunction_Start_RoutineServices_Routine_3101FE0E_Test_Pattern_Control_Start: operation=RoutineServices_Routine_3101FE0E_Test_Pattern_Control_Start.Start
            OpServerCallDcm_MainFunction_Stop_RoutineServices_Routine_3101FE0E_Test_Pattern_Control_Start: operation=RoutineServices_Routine_3101FE0E_Test_Pattern_Control_Start.Stop
            OpServerCallDcm_MainFunction_Start_RoutineServices_Routine_3101FF03_Test_Read_PMIC_Register_Start: operation=RoutineServices_Routine_3101FF03_Test_Read_PMIC_Register_Start.Start
            OpServerCallDcm_MainFunction_ReadData_DataServices_Data_22FD01_Previous_Camera_Calibration_Data: operation=DataServices_Data_22FD01_Previous_Camera_Calibration_Data.ReadData
            OpServerCallDcm_MainFunction_ReadData_DataServices_Data_22FD60_ECU_Software_Status_Read: operation=DataServices_Data_22FD60_ECU_Software_Status_Read.ReadData
            OpServerCallDcm_MainFunction_ReadData_DataServices_Data_22FD14_FD14_Magna_Production_Date_Read: operation=DataServices_Data_22FD14_FD14_Magna_Production_Date_Read.ReadData
            OpServerCallDcm_MainFunction_ReadData_DataServices_Data_22FD38_Programmed_Assembly: operation=DataServices_Data_22FD38_Programmed_Assembly.ReadData
            OpServerCallDcm_MainFunction_ReadData_DataServices_Data_22FD00_Plant_Camera_Calibration_Data: operation=DataServices_Data_22FD00_Plant_Camera_Calibration_Data.ReadData
            OpServerCallDcm_MainFunction_WriteData_DataServices_Data_22FD00_Plant_Camera_Calibration_Data: operation=DataServices_Data_22FD00_Plant_Camera_Calibration_Data.WriteData
            OpServerCallDcm_MainFunction_ReadData_DataServices_Data_225305_SPM_Event_Abort_3_Read: operation=DataServices_Data_225305_SPM_Event_Abort_3_Read.ReadData
            OpServerCallDcm_MainFunction_ReadData_DataServices_Data_22FD1D_PCB_Serial_Number: operation=DataServices_Data_22FD1D_PCB_Serial_Number.ReadData
            OpServerCallDcm_MainFunction_ReadData_DataServices_Data_22FD13_Magna_Software_Version: operation=DataServices_Data_22FD13_Magna_Software_Version.ReadData
            OpServerCallDcm_MainFunction_Start_RoutineServices_Routine_31011000_USS_Debug_Signals_Enable_Disable_Start: operation=RoutineServices_Routine_31011000_USS_Debug_Signals_Enable_Disable_Start.Start
            OpServerCallDcm_MainFunction_Start_RoutineServices_Routine_31013000_XCP_Enable_Disable_Start: operation=RoutineServices_Routine_31013000_XCP_Enable_Disable_Start.Start
            OpServerCallDcm_MainFunction_ReadData_DataServices_Data_22F111_Public_Certificates_Regional_Support_Read: operation=DataServices_Data_22F111_Public_Certificates_Regional_Support_Read.ReadData
            OpServerCallDcm_MainFunction_ReadData_DataServices_Data_222032_Secure_Log_Read: operation=DataServices_Data_222032_Secure_Log_Read.ReadData
            OpServerCallDcm_MainFunction_ReadData_DataServices_Data_222959_Hosted_App_Firmware_Cal_Config_Data_Header_Info_Read: operation=DataServices_Data_222959_Hosted_App_Firmware_Cal_Config_Data_Header_Info_Read.ReadData
            OpServerCallDcm_MainFunction_ReadData_DataServices_Data_22100C_Security_Status_Read: operation=DataServices_Data_22100C_Security_Status_Read.ReadData
            OpServerCallDcm_MainFunction_ReadData_DataServices_Data_222954_Policy_Type_Read: operation=DataServices_Data_222954_Policy_Type_Read.ReadData
            OpServerCallDcm_MainFunction_ReadData_DataServices_Data_222030_Authenticated_Diagnostic_Previous_Access_Read: operation=DataServices_Data_222030_Authenticated_Diagnostic_Previous_Access_Read.ReadData
            OpServerCallDcm_MainFunction_WriteData_DataServices_Data_2EFD4E_Reset_NVM_Write: operation=DataServices_Data_2EFD4E_Reset_NVM_Write.WriteData
            OpServerCallDcm_MainFunction_ReadData_DataServices_Data_22FD64_ASIL_B_Fault_Status_Read: operation=DataServices_Data_22FD64_ASIL_B_Fault_Status_Read.ReadData
            OpServerCallDcm_MainFunction_ReadData_DataServices_Data_220108_Authenticated_Diagnostics_Active_Role_Read: operation=DataServices_Data_220108_Authenticated_Diagnostics_Active_Role_Read.ReadData
            OpServerCallDcm_MainFunction_ReadData_DataServices_Data_22295F_DCL_and_Cerstore_Header_Info_Read: operation=DataServices_Data_22295F_DCL_and_Cerstore_Header_Info_Read.ReadData
            OpServerCallDcm_MainFunction_ReadData_DataServices_Data_222031_Disallowed_Certificate_List_Read: operation=DataServices_Data_222031_Disallowed_Certificate_List_Read.ReadData
            OpServerCallDcm_MainFunction_ReadData_DataServices_Data_22295A_Hosted_App_Firmware_Cal_Config_Data_Header_UUID_Read: operation=DataServices_Data_22295A_Hosted_App_Firmware_Cal_Config_Data_Header_UUID_Read.ReadData
            OpServerCallDcm_MainFunction_ReadData_DataServices_Data_222958_Hosted_App_firmware_Header_UUID_Read: operation=DataServices_Data_222958_Hosted_App_firmware_Header_UUID_Read.ReadData
            OpServerCallDcm_MainFunction_ReadData_DataServices_Data_222957_Hosted_App_Firmware_Header_Info_Read: operation=DataServices_Data_222957_Hosted_App_Firmware_Header_Info_Read.ReadData
            OpServerCallDcm_MainFunction_ReadData_DataServices_Data_22FD62_ASIL_QM_Fault_Status_Read: operation=DataServices_Data_22FD62_ASIL_QM_Fault_Status_Read.ReadData
            OpServerCallDcm_MainFunction_ReadData_DataServices_Data_22FD86_Functional_Settings_Read: operation=DataServices_Data_22FD86_Functional_Settings_Read.ReadData
            OpServerCallDcm_MainFunction_WriteData_DataServices_Data_22FD86_Functional_Settings_Read: operation=DataServices_Data_22FD86_Functional_Settings_Read.WriteData
            OpServerCallDcm_MainFunction_ReadData_DataServices_Data_225109_Rear_Sensor_HealthBlockage_LiveDetection_Check_Read: operation=DataServices_Data_225109_Rear_Sensor_HealthBlockage_LiveDetection_Check_Read.ReadData
            OpServerCallDcm_MainFunction_ReadData_DataServices_Data_225107_Front_Sensor_HealthBlockage_LiveDetection_Check_Read: operation=DataServices_Data_225107_Front_Sensor_HealthBlockage_LiveDetection_Check_Read.ReadData
            OpServerCallDcm_MainFunction_ReadData_DataServices_Data_22FD4A_Ultrasonic_Sensors_Power_supply_and_Current_Level_Read: operation=DataServices_Data_22FD4A_Ultrasonic_Sensors_Power_supply_and_Current_Level_Read.ReadData
            OpServerCallDcm_MainFunction_ReadData_DataServices_Data_22FD65_FuSa_Module_Status_Read: operation=DataServices_Data_22FD65_FuSa_Module_Status_Read.ReadData
            OpServerCallDcm_MainFunction_ReadData_DataServices_Data_222951_Certificate_Store_UUID_Read: operation=DataServices_Data_222951_Certificate_Store_UUID_Read.ReadData
            OpServerCallDcm_MainFunction_ReadData_DataServices_Data_22FD66_Camera_occlusion_and_low_light_status_Read: operation=DataServices_Data_22FD66_Camera_occlusion_and_low_light_status_Read.ReadData
            OpServerCallDcm_MainFunction_ReadData_DataServices_Data_22FD67_Camera_DLD_Status_Read: operation=DataServices_Data_22FD67_Camera_DLD_Status_Read.ReadData
            OpServerCallDcm_MainFunction_ReadData_DataServices_Data_22295B_HTA_Header_Info_Read: operation=DataServices_Data_22295B_HTA_Header_Info_Read.ReadData
            OpServerCallDcm_MainFunction_ReadData_DataServices_Data_22FD43_Active_Safe_State_Read: operation=DataServices_Data_22FD43_Active_Safe_State_Read.ReadData
            OpServerCallDcm_MainFunction_ReadData_DataServices_Data_22FD44_Error_Flags_Read: operation=DataServices_Data_22FD44_Error_Flags_Read.ReadData
            OpServerCallDcm_MainFunction_ReadData_DataServices_Data_22295E_DCL_Header_UUID_Read: operation=DataServices_Data_22295E_DCL_Header_UUID_Read.ReadData
            OpServerCallDcm_MainFunction_ReadData_DataServices_Data_22295C_HTA_Header_UUID_Read: operation=DataServices_Data_22295C_HTA_Header_UUID_Read.ReadData
            OpServerCallDcm_MainFunction_ReadData_DataServices_Data_22FD74_PHY_Tunning_Error_And_Buffer_Mark_Error_Read: operation=DataServices_Data_22FD74_PHY_Tunning_Error_And_Buffer_Mark_Error_Read.ReadData
            OpServerCallDcm_MainFunction_Start_RoutineServices_Routine_31015502_TRSC_Trailer_Calibration_Memory_Clear_Start: operation=RoutineServices_Routine_31015502_TRSC_Trailer_Calibration_Memory_Clear_Start.Start
            OpServerCallDcm_MainFunction_RequestResults_RoutineServices_Routine_31015502_TRSC_Trailer_Calibration_Memory_Clear_Start: operation=RoutineServices_Routine_31015502_TRSC_Trailer_Calibration_Memory_Clear_Start.RequestResults
            OpServerCallDcm_MainFunction_ReadData_DataServices_Data_22FDF7_Intrinsic_Camera_NvM_Data_Read: operation=DataServices_Data_22FDF7_Intrinsic_Camera_NvM_Data_Read.ReadData
            OpServerCallDcm_MainFunction_ReadData_DataServices_Data_22FDF6_RunTimeStatsData_Read: operation=DataServices_Data_22FDF6_RunTimeStatsData_Read.ReadData
            OpServerCallDcm_MainFunction_ReadData_DataServices_Data_22FD04_USS_Sensor_tuning_values_Read: operation=DataServices_Data_22FD04_USS_Sensor_tuning_values_Read.ReadData
            OpServerCallDcm_MainFunction_ReadDataLength_DataServices_Data_22FD04_USS_Sensor_tuning_values_Read: operation=DataServices_Data_22FD04_USS_Sensor_tuning_values_Read.ReadDataLength
            OpServerCallDcm_MainFunction_WriteData_DataServices_Data_22FD04_USS_Sensor_tuning_values_Read: operation=DataServices_Data_22FD04_USS_Sensor_tuning_values_Read.WriteData
            OpServerCallDcm_MainFunction_ReadData_DataServices_Data_22FDF8_StackUsage_Read: operation=DataServices_Data_22FDF8_StackUsage_Read.ReadData
            OpServerCallDcm_MainFunction_ReadData_DataServices_Data_22FDF5_PerformanceStatEnable_Read: operation=DataServices_Data_22FDF5_PerformanceStatEnable_Read.ReadData
            OpServerCallDcm_MainFunction_WriteData_DataServices_Data_22FDF5_PerformanceStatEnable_Read: operation=DataServices_Data_22FDF5_PerformanceStatEnable_Read.WriteData
        GetActiveProtocol: can-be-invoked-concurrently=true, symbol=Dcm_GetActiveProtocol
        GetSesCtrlType: can-be-invoked-concurrently=true, symbol=Dcm_GetSesCtrlType
        ResetToDefaultSession: can-be-invoked-concurrently=true, symbol=Dcm_ResetToDefaultSession
        GetSecurityLevel: can-be-invoked-concurrently=true, symbol=Dcm_GetSecurityLevel
        SetActiveDiagnostic: can-be-invoked-concurrently=true, symbol=Dcm_SetActiveDiagnostic
        GetRequestKind: can-be-invoked-concurrently=true, symbol=Dcm_GetRequestKind
  swc implementation DcmImplementation: programming-language=C, behavior=DcmInternalBehavior
    resource consumption DcmResourceConsumption
      5 x memory section:
        Dcm_START_SEC_CODE: sw-addrmethod=CODE, symbol=CODE
        Dcm_START_SEC_CONST_UNSPECIFIED: alignment=UNSPECIFIED, sw-addrmethod=CONST, symbol=CONST_UNSPECIFIED
        Dcm_START_SEC_VAR_NOINIT_UNSPECIFIED: alignment=UNSPECIFIED, sw-addrmethod=VAR_NO_INIT, symbol=VAR_NOINIT_UNSPECIFIED
        Dcm_START_SEC_VAR_INIT_UNSPECIFIED: alignment=UNSPECIFIED, sw-addrmethod=VAR_INIT, symbol=VAR_INIT_UNSPECIFIED
        Dcm_START_SEC_VAR_ZERO_INIT_UNSPECIFIED: alignment=UNSPECIFIED, sw-addrmethod=VAR_CLEARED, symbol=VAR_ZERO_INIT_UNSPECIFIED
